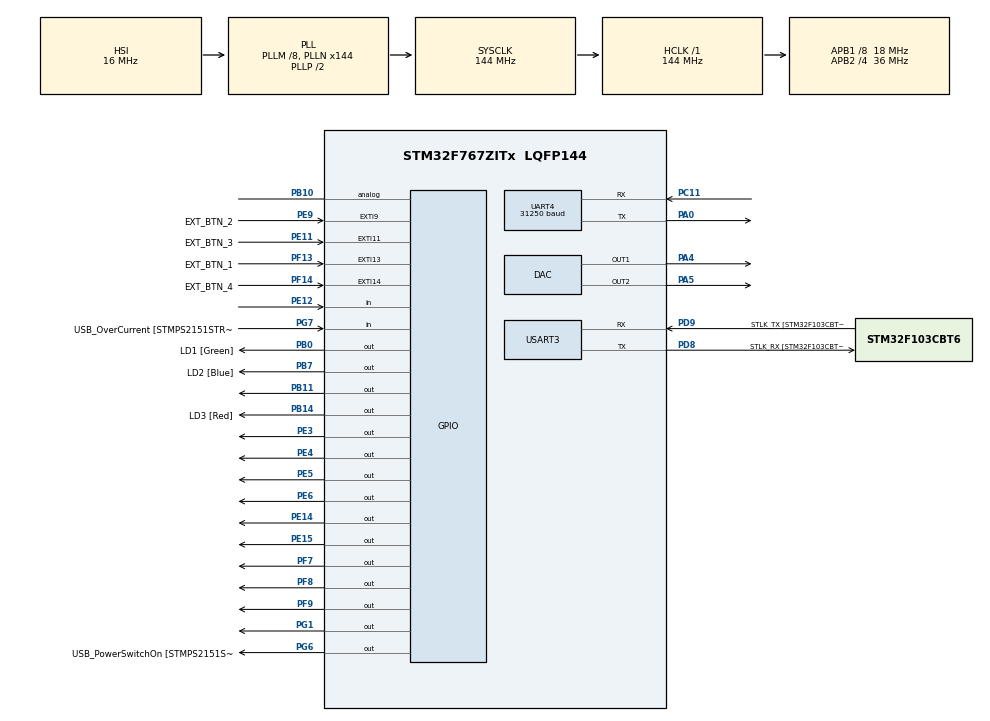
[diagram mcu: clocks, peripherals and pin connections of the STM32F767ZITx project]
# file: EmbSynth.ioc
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CORTEX_M7.CPU_ICache=Disabled
CORTEX_M7.FlashInterface=AXI_Enabled
DAC.DAC_OutputBuffer=DAC_OUTPUTBUFFER_ENABLE
DAC.DAC_Trigger=DAC_TRIGGER_T6_TRGO
DAC.DAC_Trigger2=DAC_TRIGGER_T6_TRGO
Dma.DAC1.1.Direction=DMA_MEMORY_TO_PERIPH
Dma.DAC1.1.FIFOMode=DMA_FIFOMODE_DISABLE
Dma.DAC1.1.Instance=DMA1_Stream5
Dma.DAC1.1.MemDataAlignment=DMA_MDATAALIGN_WORD
Dma.DAC1.1.MemInc=DMA_MINC_ENABLE
Dma.DAC1.1.Mode=DMA_CIRCULAR
Dma.DAC1.1.PeriphDataAlignment=DMA_PDATAALIGN_WORD
Dma.DAC1.1.PeriphInc=DMA_PINC_DISABLE
Dma.DAC1.1.Priority=DMA_PRIORITY_HIGH
Dma.DAC2.2.Direction=DMA_MEMORY_TO_PERIPH
Dma.DAC2.2.FIFOMode=DMA_FIFOMODE_DISABLE
Dma.DAC2.2.Instance=DMA1_Stream6
Dma.DAC2.2.MemDataAlignment=DMA_MDATAALIGN_WORD
Dma.DAC2.2.MemInc=DMA_MINC_ENABLE
Dma.DAC2.2.Mode=DMA_CIRCULAR
Dma.DAC2.2.PeriphDataAlignment=DMA_PDATAALIGN_WORD
Dma.DAC2.2.PeriphInc=DMA_PINC_DISABLE
Dma.DAC2.2.Priority=DMA_PRIORITY_HIGH
Dma.Request0=UART4_RX
Dma.Request1=DAC1
Dma.Request2=DAC2
Dma.UART4_RX.0.Direction=DMA_PERIPH_TO_MEMORY
Dma.UART4_RX.0.FIFOMode=DMA_FIFOMODE_DISABLE
Dma.UART4_RX.0.Instance=DMA1_Stream2
Dma.UART4_RX.0.MemDataAlignment=DMA_MDATAALIGN_BYTE
Dma.UART4_RX.0.MemInc=DMA_MINC_ENABLE
Dma.UART4_RX.0.Mode=DMA_CIRCULAR
Dma.UART4_RX.0.PeriphDataAlignment=DMA_PDATAALIGN_BYTE
Dma.UART4_RX.0.PeriphInc=DMA_PINC_DISABLE
Dma.UART4_RX.0.Priority=DMA_PRIORITY_HIGH
Mcu.Family=STM32F7
Mcu.Name=STM32F767ZITx
Mcu.Package=LQFP144
NVIC.DMA1_Stream2_IRQn=true\:0\:0\:false\:false\:true\:false\:true
NVIC.DMA1_Stream5_IRQn=true\:0\:0\:false\:false\:true\:false\:true
NVIC.DMA1_Stream6_IRQn=true\:0\:0\:false\:false\:true\:false\:true
NVIC.EXTI15_10_IRQn=true\:0\:0\:false\:false\:true\:true\:true
NVIC.EXTI9_5_IRQn=true\:0\:0\:false\:false\:true\:true\:true
NVIC.PriorityGroup=NVIC_PRIORITYGROUP_4
NVIC.TIM2_IRQn=true\:0\:0\:false\:false\:true\:true\:true
PA0/WKUP.Mode=Asynchronous
PA0/WKUP.Signal=UART4_TX
PA1.GPIO_Label=RMII_REF_CLK [LAN8742A-CZ-TR_REFCLK0]
PA1.Signal=ETH_REF_CLK
PA10.GPIO_Label=USB_ID
PA10.Signal=USB_OTG_FS_ID
PA11.GPIO_Label=USB_DM
PA11.Signal=USB_OTG_FS_DM
PA12.GPIO_Label=USB_DP
PA12.Signal=USB_OTG_FS_DP
PA13.GPIO_Label=TMS
PA13.Mode=Serial_Wire
PA13.Signal=SYS_JTMS-SWDIO
PA14.GPIO_Label=TCK
PA14.Mode=Serial_Wire
PA14.Signal=SYS_JTCK-SWCLK
PA2.GPIO_Label=RMII_MDIO [LAN8742A-CZ-TR_MDIO]
PA2.Signal=ETH_MDIO
PA4.Signal=COMP_DAC1_group
PA5.Signal=COMP_DAC2_group
PA7.GPIO_Label=RMII_CRS_DV [LAN8742A-CZ-TR_CRS_DV]
PA7.Signal=ETH_CRS_DV
PA8.GPIO_Label=USB_SOF [TP1]
PA8.Signal=USB_OTG_FS_SOF
PA9.GPIO_Label=USB_VBUS
PA9.Signal=USB_OTG_FS_VBUS
PB0.GPIO_Label=LD1 [Green]
PB0.Signal=GPIO_Output
PB10.Signal=GPIO_Analog
PB11.Signal=GPIO_Output
PB13.GPIO_Label=RMII_TXD1 [LAN8742A-CZ-TR_TXD1]
PB13.Signal=ETH_TXD1
PB14.GPIO_Label=LD3 [Red]
PB14.Signal=GPIO_Output
PB3.GPIO_Label=SWO
PB3.Signal=SYS_JTDO-SWO
PB7.GPIO_Label=LD2 [Blue]
PB7.Signal=GPIO_Output
PC1.GPIO_Label=RMII_MDC [LAN8742A-CZ-TR_MDC]
PC1.Signal=ETH_MDC
PC11.Mode=Asynchronous
PC11.Signal=UART4_RX
PC14/OSC32_IN.Mode=LSE-External-Oscillator
PC14/OSC32_IN.Signal=RCC_OSC32_IN
PC15/OSC32_OUT.Mode=LSE-External-Oscillator
PC15/OSC32_OUT.Signal=RCC_OSC32_OUT
PC4.GPIO_Label=RMII_RXD0 [LAN8742A-CZ-TR_RXD0]
PC4.Signal=ETH_RXD0
PC5.GPIO_Label=RMII_RXD1 [LAN8742A-CZ-TR_RXD1]
PC5.Signal=ETH_RXD1
PD8.GPIO_Label=STLK_RX [STM32F103CBT6_PA3]
PD8.Mode=Asynchronous
PD8.Signal=USART3_TX
PD9.GPIO_Label=STLK_TX [STM32F103CBT6_PA2]
PD9.Mode=Asynchronous
PD9.Signal=USART3_RX
PE11.GPIO_Label=EXT_BTN_3
PE11.GPIO_ModeDefaultEXTI=GPIO_MODE_IT_FALLING
PE11.GPIO_PuPd=GPIO_PULLUP
PE11.Signal=GPXTI11
PE12.Signal=GPIO_Input
PE14.Signal=GPIO_Output
PE15.Signal=GPIO_Output
PE3.Signal=GPIO_Output
PE4.Signal=GPIO_Output
PE5.Signal=GPIO_Output
PE6.Signal=GPIO_Output
PE9.GPIO_Label=EXT_BTN_2
PE9.GPIO_ModeDefaultEXTI=GPIO_MODE_IT_FALLING
PE9.GPIO_PuPd=GPIO_PULLUP
PE9.Signal=GPXTI9
PF13.GPIO_Label=EXT_BTN_1
PF13.GPIO_ModeDefaultEXTI=GPIO_MODE_IT_FALLING
PF13.GPIO_PuPd=GPIO_PULLUP
PF13.Signal=GPXTI13
PF14.GPIO_Label=EXT_BTN_4
PF14.GPIO_ModeDefaultEXTI=GPIO_MODE_IT_FALLING
PF14.GPIO_PuPd=GPIO_PULLUP
PF14.Signal=GPXTI14
PF7.Signal=GPIO_Output
PF8.Signal=GPIO_Output
PF9.Signal=GPIO_Output
PG1.Signal=GPIO_Output
PG11.GPIO_Label=RMII_TX_EN [LAN8742A-CZ-TR_TXEN]
PG11.Signal=ETH_TX_EN
PG13.GPIO_Label=RMII_TXD0 [LAN8742A-CZ-TR_TXD0]
PG13.Signal=ETH_TXD0
PG6.GPIO_Label=USB_PowerSwitchOn [STMPS2151STR_EN]
PG6.Signal=GPIO_Output
PG7.GPIO_Label=USB_OverCurrent [STMPS2151STR_FAULT]
PG7.Signal=GPIO_Input
PH0/OSC_IN.GPIO_Label=MCO [STM32F103CBT6_PA8]
PH0/OSC_IN.Signal=RCC_OSC_IN
PH1/OSC_OUT.Signal=RCC_OSC_OUT
ProjectManager.HeapSize=0x200
ProjectManager.StackSize=0x400
ProjectManager.TargetToolchain=STM32CubeIDE
RCC.48MHZClocksFreq_Value=24000000
RCC.AHBFreq_Value=144000000
RCC.APB1CLKDivider=RCC_HCLK_DIV8
RCC.APB1Freq_Value=18000000
RCC.APB1TimFreq_Value=36000000
RCC.APB2CLKDivider=RCC_HCLK_DIV4
RCC.APB2Freq_Value=36000000
RCC.APB2TimFreq_Value=72000000
RCC.CortexFreq_Value=144000000
RCC.HCLKFreq_Value=144000000
RCC.HSE_VALUE=8000000
RCC.HSI_VALUE=16000000
RCC.PLLM=8
RCC.PLLMUL=RCC_PLL_MUL9
RCC.PLLN=144
RCC.PLLQ=4
RCC.PRESCALERUSB=RCC_USBCLKSOURCE_PLL_DIV1_5
RCC.SYSCLKFreq_VALUE=144000000
RCC.SYSCLKSource=RCC_SYSCLKSOURCE_PLLCLK
RCC.SYSCLKSourceVirtual=RCC_SYSCLKSOURCE_PLLCLK
RCC.USBFreq_Value=72000000
RCC.VCOOutputFreq_Value=288000000
SH.COMP_DAC1_group.0=DAC_OUT1,DAC_OUT1
SH.COMP_DAC2_group.0=DAC_OUT2,DAC_OUT2
TIM1.Period=0xffff-1
TIM1.Prescaler=72-1
TIM2.Period=40-1
TIM2.Prescaler=36000-1
TIM6.Period=15-1
TIM6.Prescaler=55-1
TIM6.TIM_MasterOutputTrigger=TIM_TRGO_UPDATE
UART4.BaudRate=31250
USART3.VirtualMode-Asynchronous=VM_ASYNC
VP_TIM1_VS_ClockSourceINT.Mode=Internal
VP_TIM2_VS_ClockSourceINT.Mode=Internal
VP_TIM6_VS_ClockSourceINT.Mode=Enable_Timer
board=NUCLEO-F767ZI

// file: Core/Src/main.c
/* USER CODE BEGIN Header */
/**
 ******************************************************************************
 * @file           : main.c
 * @brief          : Main program body
 ******************************************************************************
 * @attention
 *
 * <h2><center>&copy; Copyright (c) 2020 STMicroelectronics.
 * All rights reserved.</center></h2>
 *
 * This software component is licensed by ST under BSD 3-Clause license,
 * the "License"; You may not use this file except in compliance with the
 * License. You may obtain a copy of the License at:
 *                        opensource.org/licenses/BSD-3-Clause
 *
 ******************************************************************************
 */
/* USER CODE END Header */
#include "main.h"

/* USER CODE BEGIN Includes */
#include <stdbool.h>
#include "math.h"
#include "fonts.h"
#include "tft.h"
#include "functions.h"
/* USER CODE END Includes */

/* USER CODE BEGIN PD */
#define RX_BUFFER_SIZE 1
#define NOTE_BUFFER_SIZE 1
#define PLAYED_NOTES_BUFFER_SIZE 5
#define C2 36
#define B5 83
#define NS 500
#define PI 3.1415926
/* USER CODE END PD */

DAC_HandleTypeDef hdac;
DMA_HandleTypeDef hdma_dac1;
DMA_HandleTypeDef hdma_dac2;

TIM_HandleTypeDef htim1;
TIM_HandleTypeDef htim2;
TIM_HandleTypeDef htim6;

UART_HandleTypeDef huart4;
UART_HandleTypeDef huart3;
DMA_HandleTypeDef hdma_uart4_rx;

/* USER CODE BEGIN PV */

// LCD
uint16_t ID = 0;
uint8_t current_am_selection = 0;
uint8_t current_fm_selection = 0;
uint8_t current_envelope_selection = 0;
uint8_t current_signal_selection = 0;

// Serial
uint8_t rx_buffer[RX_BUFFER_SIZE] = {0};
uint8_t note_buffer[NOTE_BUFFER_SIZE] = {0};
uint8_t note_cnt = 0;
uint8_t received_note_buffer = 0;
bool repeated_note_flag = false;

// Interrupción
volatile bool EXT_BTN_1_state = true;
volatile bool EXT_BTN_2_state = true;
volatile bool EXT_BTN_3_state = true;
volatile bool EXT_BTN_4_state = true;

// Audio
uint8_t played_notes_buffer[PLAYED_NOTES_BUFFER_SIZE] = {0};

uint16_t sine_LUT [] = {
		2048, 2073, 2099, 2125, 2151, 2176, 2202, 2228, 2253, 2279, 2305, 2330, 2356, 2381, 2407,
		2432, 2457, 2482, 2508, 2533, 2558, 2583, 2607, 2632, 2657, 2681, 2706, 2730, 2755, 2779,
		2803, 2827, 2850, 2874, 2898, 2921, 2944, 2967, 2990, 3013, 3036, 3058, 3081, 3103, 3125,
		3147, 3168, 3190, 3211, 3232, 3253, 3274, 3294, 3315, 3335, 3355, 3375, 3394, 3413, 3432,
		3451, 3470, 3488, 3507, 3525, 3542, 3560, 3577, 3594, 3611, 3627, 3644, 3660, 3675, 3691,
		3706, 3721, 3736, 3750, 3765, 3778, 3792, 3805, 3819, 3831, 3844, 3856, 3868, 3880, 3891,
		3902, 3913, 3923, 3934, 3943, 3953, 3962, 3971, 3980, 3988, 3996, 4004, 4012, 4019, 4026,
		4032, 4038, 4044, 4050, 4055, 4060, 4064, 4069, 4073, 4076, 4080, 4083, 4085, 4088, 4090,
		4091, 4093, 4094, 4095, 4095, 4095, 4095, 4094, 4093, 4092, 4091, 4089, 4086, 4084, 4081,
		4078, 4074, 4071, 4067, 4062, 4057, 4052, 4047, 4041, 4035, 4029, 4022, 4015, 4008, 4000,
		3992, 3984, 3976, 3967, 3958, 3948, 3939, 3928, 3918, 3908, 3897, 3885, 3874, 3862, 3850,
		3838, 3825, 3812, 3799, 3785, 3772, 3758, 3743, 3729, 3714, 3699, 3683, 3668, 3652, 3636,
		3619, 3603, 3586, 3569, 3551, 3534, 3516, 3498, 3479, 3461, 3442, 3423, 3404, 3384, 3365,
		3345, 3325, 3305, 3284, 3263, 3243, 3222, 3200, 3179, 3157, 3136, 3114, 3092, 3069, 3047,
		3024, 3002, 2979, 2956, 2933, 2909, 2886, 2862, 2838, 2815, 2791, 2767, 2742, 2718, 2694,
		2669, 2645, 2620, 2595, 2570, 2545, 2520, 2495, 2470, 2445, 2419, 2394, 2368, 2343, 2317,
		2292, 2266, 2241, 2215, 2189, 2163, 2138, 2112, 2086, 2060, 2035, 2009, 1983, 1957, 1932,
		1906, 1880, 1854, 1829, 1803, 1778, 1752, 1727, 1701, 1676, 1650, 1625, 1600, 1575, 1550,
		1525, 1500, 1475, 1450, 1426, 1401, 1377, 1353, 1328, 1304, 1280, 1257, 1233, 1209, 1186,
		1162, 1139, 1116, 1093, 1071, 1048, 1026, 1003, 981, 959, 938, 916, 895, 873, 852,
		832, 811, 790, 770, 750, 730, 711, 691, 672, 653, 634, 616, 597, 579, 561,
		544, 526, 509, 492, 476, 459, 443, 427, 412, 396, 381, 366, 352, 337, 323,
		310, 296, 283, 270, 257, 245, 233, 221, 210, 198, 187, 177, 167, 156, 147,
		137, 128, 119, 111, 103, 95, 87, 80, 73, 66, 60, 54, 48, 43, 38,
		33, 28, 24, 21, 17, 14, 11, 9, 6, 4, 3, 2, 1, 0, 0,
		0, 0, 1, 2, 4, 5, 7, 10, 12, 15, 19, 22, 26, 31, 35,
		40, 45, 51, 57, 63, 69, 76, 83, 91, 99, 107, 115, 124, 133, 142,
		152, 161, 172, 182, 193, 204, 215, 227, 239, 251, 264, 276, 290, 303, 317,
		330, 345, 359, 374, 389, 404, 420, 435, 451, 468, 484, 501, 518, 535, 553,
		570, 588, 607, 625, 644, 663, 682, 701, 720, 740, 760, 780, 801, 821, 842,
		863, 884, 905, 927, 948, 970, 992, 1014, 1037, 1059, 1082, 1105, 1128, 1151, 1174,
		1197, 1221, 1245, 1268, 1292, 1316, 1340, 1365, 1389, 1414, 1438, 1463, 1488, 1512, 1537,
		1562, 1587, 1613, 1638, 1663, 1688, 1714, 1739, 1765, 1790, 1816, 1842, 1867, 1893, 1919,
		1944, 1970, 1996, 2022, 2047
};

uint16_t sawtooth_LUT [] = {
		0, 8, 16, 25, 33, 41, 49, 57, 66, 74, 82, 90, 98, 107, 115,
		123, 131, 140, 148, 156, 164, 172, 181, 189, 197, 205, 213, 222, 230, 238,
		246, 254, 263, 271, 279, 287, 295, 304, 312, 320, 328, 336, 345, 353, 361,
		369, 377, 386, 394, 402, 410, 419, 427, 435, 443, 451, 460, 468, 476, 484,
		492, 501, 509, 517, 525, 533, 542, 550, 558, 566, 574, 583, 591, 599, 607,
		615, 624, 632, 640, 648, 657, 665, 673, 681, 689, 698, 706, 714, 722, 730,
		739, 747, 755, 763, 771, 780, 788, 796, 804, 812, 821, 829, 837, 845, 853,
		862, 870, 878, 886, 894, 903, 911, 919, 927, 936, 944, 952, 960, 968, 977,
		985, 993, 1001, 1009, 1018, 1026, 1034, 1042, 1050, 1059, 1067, 1075, 1083, 1091, 1100,
		1108, 1116, 1124, 1132, 1141, 1149, 1157, 1165, 1174, 1182, 1190, 1198, 1206, 1215, 1223,
		1231, 1239, 1247, 1256, 1264, 1272, 1280, 1288, 1297, 1305, 1313, 1321, 1329, 1338, 1346,
		1354, 1362, 1370, 1379, 1387, 1395, 1403, 1412, 1420, 1428, 1436, 1444, 1453, 1461, 1469,
		1477, 1485, 1494, 1502, 1510, 1518, 1526, 1535, 1543, 1551, 1559, 1567, 1576, 1584, 1592,
		1600, 1608, 1617, 1625, 1633, 1641, 1649, 1658, 1666, 1674, 1682, 1691, 1699, 1707, 1715,
		1723, 1732, 1740, 1748, 1756, 1764, 1773, 1781, 1789, 1797, 1805, 1814, 1822, 1830, 1838,
		1846, 1855, 1863, 1871, 1879, 1887, 1896, 1904, 1912, 1920, 1929, 1937, 1945, 1953, 1961,
		1970, 1978, 1986, 1994, 2002, 2011, 2019, 2027, 2035, 2043, 2052, 2060, 2068, 2076, 2084,
		2093, 2101, 2109, 2117, 2125, 2134, 2142, 2150, 2158, 2166, 2175, 2183, 2191, 2199, 2208,
		2216, 2224, 2232, 2240, 2249, 2257, 2265, 2273, 2281, 2290, 2298, 2306, 2314, 2322, 2331,
		2339, 2347, 2355, 2363, 2372, 2380, 2388, 2396, 2404, 2413, 2421, 2429, 2437, 2446, 2454,
		2462, 2470, 2478, 2487, 2495, 2503, 2511, 2519, 2528, 2536, 2544, 2552, 2560, 2569, 2577,
		2585, 2593, 2601, 2610, 2618, 2626, 2634, 2642, 2651, 2659, 2667, 2675, 2683, 2692, 2700,
		2708, 2716, 2725, 2733, 2741, 2749, 2757, 2766, 2774, 2782, 2790, 2798, 2807, 2815, 2823,
		2831, 2839, 2848, 2856, 2864, 2872, 2880, 2889, 2897, 2905, 2913, 2921, 2930, 2938, 2946,
		2954, 2963, 2971, 2979, 2987, 2995, 3004, 3012, 3020, 3028, 3036, 3045, 3053, 3061, 3069,
		3077, 3086, 3094, 3102, 3110, 3118, 3127, 3135, 3143, 3151, 3159, 3168, 3176, 3184, 3192,
		3201, 3209, 3217, 3225, 3233, 3242, 3250, 3258, 3266, 3274, 3283, 3291, 3299, 3307, 3315,
		3324, 3332, 3340, 3348, 3356, 3365, 3373, 3381, 3389, 3397, 3406, 3414, 3422, 3430, 3438,
		3447, 3455, 3463, 3471, 3480, 3488, 3496, 3504, 3512, 3521, 3529, 3537, 3545, 3553, 3562,
		3570, 3578, 3586, 3594, 3603, 3611, 3619, 3627, 3635, 3644, 3652, 3660, 3668, 3676, 3685,
		3693, 3701, 3709, 3718, 3726, 3734, 3742, 3750, 3759, 3767, 3775, 3783, 3791, 3800, 3808,
		3816, 3824, 3832, 3841, 3849, 3857, 3865, 3873, 3882, 3890, 3898, 3906, 3914, 3923, 3931,
		3939, 3947, 3955, 3964, 3972, 3980, 3988, 3997, 4005, 4013, 4021, 4029, 4038, 4046, 4054,
		4062, 4070, 4079, 4087, 0
};

uint16_t triangle_LUT [] = {
		0, 16, 33, 49, 66, 82, 98, 115, 131, 148, 164, 181, 197, 213, 230,
		246, 263, 279, 295, 312, 328, 345, 361, 377, 394, 410, 427, 443, 460, 476,
		492, 509, 525, 542, 558, 574, 591, 607, 624, 640, 657, 673, 689, 706, 722,
		739, 755, 771, 788, 804, 821, 837, 853, 870, 886, 903, 919, 936, 952, 968,
		985, 1001, 1018, 1034, 1050, 1067, 1083, 1100, 1116, 1132, 1149, 1165, 1182, 1198, 1215,
		1231, 1247, 1264, 1280, 1297, 1313, 1329, 1346, 1362, 1379, 1395, 1412, 1428, 1444, 1461,
		1477, 1494, 1510, 1526, 1543, 1559, 1576, 1592, 1608, 1625, 1641, 1658, 1674, 1691, 1707,
		1723, 1740, 1756, 1773, 1789, 1805, 1822, 1838, 1855, 1871, 1887, 1904, 1920, 1937, 1953,
		1970, 1986, 2002, 2019, 2035, 2052, 2068, 2084, 2101, 2117, 2134, 2150, 2166, 2183, 2199,
		2216, 2232, 2249, 2265, 2281, 2298, 2314, 2331, 2347, 2363, 2380, 2396, 2413, 2429, 2446,
		2462, 2478, 2495, 2511, 2528, 2544, 2560, 2577, 2593, 2610, 2626, 2642, 2659, 2675, 2692,
		2708, 2725, 2741, 2757, 2774, 2790, 2807, 2823, 2839, 2856, 2872, 2889, 2905, 2921, 2938,
		2954, 2971, 2987, 3004, 3020, 3036, 3053, 3069, 3086, 3102, 3118, 3135, 3151, 3168, 3184,
		3201, 3217, 3233, 3250, 3266, 3283, 3299, 3315, 3332, 3348, 3365, 3381, 3397, 3414, 3430,
		3447, 3463, 3480, 3496, 3512, 3529, 3545, 3562, 3578, 3594, 3611, 3627, 3644, 3660, 3676,
		3693, 3709, 3726, 3742, 3759, 3775, 3791, 3808, 3824, 3841, 3857, 3873, 3890, 3906, 3923,
		3939, 3955, 3972, 3988, 4005, 4021, 4038, 4054, 4070, 4087, 4087, 4070, 4054, 4038, 4021,
		4005, 3988, 3972, 3955, 3939, 3923, 3906, 3890, 3873, 3857, 3841, 3824, 3808, 3791, 3775,
		3759, 3742, 3726, 3709, 3693, 3676, 3660, 3644, 3627, 3611, 3594, 3578, 3562, 3545, 3529,
		3512, 3496, 3480, 3463, 3447, 3430, 3414, 3397, 3381, 3365, 3348, 3332, 3315, 3299, 3283,
		3266, 3250, 3233, 3217, 3201, 3184, 3168, 3151, 3135, 3118, 3102, 3086, 3069, 3053, 3036,
		3020, 3004, 2987, 2971, 2954, 2938, 2921, 2905, 2889, 2872, 2856, 2839, 2823, 2807, 2790,
		2774, 2757, 2741, 2725, 2708, 2692, 2675, 2659, 2642, 2626, 2610, 2593, 2577, 2560, 2544,
		2528, 2511, 2495, 2478, 2462, 2446, 2429, 2413, 2396, 2380, 2363, 2347, 2331, 2314, 2298,
		2281, 2265, 2249, 2232, 2216, 2199, 2183, 2166, 2150, 2134, 2117, 2101, 2084, 2068, 2052,
		2035, 2019, 2002, 1986, 1970, 1953, 1937, 1920, 1904, 1887, 1871, 1855, 1838, 1822, 1805,
		1789, 1773, 1756, 1740, 1723, 1707, 1691, 1674, 1658, 1641, 1625, 1608, 1592, 1576, 1559,
		1543, 1526, 1510, 1494, 1477, 1461, 1444, 1428, 1412, 1395, 1379, 1362, 1346, 1329, 1313,
		1297, 1280, 1264, 1247, 1231, 1215, 1198, 1182, 1165, 1149, 1132, 1116, 1100, 1083, 1067,
		1050, 1034, 1018, 1001, 985, 968, 952, 936, 919, 903, 886, 870, 853, 837, 821,
		804, 788, 771, 755, 739, 722, 706, 689, 673, 657, 640, 624, 607, 591, 574,
		558, 542, 525, 509, 492, 476, 460, 443, 427, 410, 394, 377, 361, 345, 328,
		312, 295, 279, 263, 246, 230, 213, 197, 181, 164, 148, 131, 115, 98, 82,
		66, 49, 33, 16, 0
};

uint16_t square_LUT [] = {
		4095, 4095, 4095, 4095, 4095, 4095, 4095, 4095, 4095, 4095, 4095, 4095, 4095, 4095, 4095,
		4095, 4095, 4095, 4095, 4095, 4095, 4095, 4095, 4095, 4095, 4095, 4095, 4095, 4095, 4095,
		4095, 4095, 4095, 4095, 4095, 4095, 4095, 4095, 4095, 4095, 4095, 4095, 4095, 4095, 4095,
		4095, 4095, 4095, 4095, 4095, 4095, 4095, 4095, 4095, 4095, 4095, 4095, 4095, 4095, 4095,
		4095, 4095, 4095, 4095, 4095, 4095, 4095, 4095, 4095, 4095, 4095, 4095, 4095, 4095, 4095,
		4095, 4095, 4095, 4095, 4095, 4095, 4095, 4095, 4095, 4095, 4095, 4095, 4095, 4095, 4095,
		4095, 4095, 4095, 4095, 4095, 4095, 4095, 4095, 4095, 4095, 4095, 4095, 4095, 4095, 4095,
		4095, 4095, 4095, 4095, 4095, 4095, 4095, 4095, 4095, 4095, 4095, 4095, 4095, 4095, 4095,
		4095, 4095, 4095, 4095, 4095, 4095, 4095, 4095, 4095, 4095, 4095, 4095, 4095, 4095, 4095,
		4095, 4095, 4095, 4095, 4095, 4095, 4095, 4095, 4095, 4095, 4095, 4095, 4095, 4095, 4095,
		4095, 4095, 4095, 4095, 4095, 4095, 4095, 4095, 4095, 4095, 4095, 4095, 4095, 4095, 4095,
		4095, 4095, 4095, 4095, 4095, 4095, 4095, 4095, 4095, 4095, 4095, 4095, 4095, 4095, 4095,
		4095, 4095, 4095, 4095, 4095, 4095, 4095, 4095, 4095, 4095, 4095, 4095, 4095, 4095, 4095,
		4095, 4095, 4095, 4095, 4095, 4095, 4095, 4095, 4095, 4095, 4095, 4095, 4095, 4095, 4095,
		4095, 4095, 4095, 4095, 4095, 4095, 4095, 4095, 4095, 4095, 4095, 4095, 4095, 4095, 4095,
		4095, 4095, 4095, 4095, 4095, 4095, 4095, 4095, 4095, 4095, 4095, 4095, 4095, 4095, 4095,
		4095, 4095, 4095, 4095, 4095, 4095, 4095, 4095, 4095, 4095, 0, 0, 0, 0, 0,
		0, 0, 0, 0, 0, 0, 0, 0, 0, 0, 0, 0, 0, 0, 0,
		0, 0, 0, 0, 0, 0, 0, 0, 0, 0, 0, 0, 0, 0, 0,
		0, 0, 0, 0, 0, 0, 0, 0, 0, 0, 0, 0, 0, 0, 0,
		0, 0, 0, 0, 0, 0, 0, 0, 0, 0, 0, 0, 0, 0, 0,
		0, 0, 0, 0, 0, 0, 0, 0, 0, 0, 0, 0, 0, 0, 0,
		0, 0, 0, 0, 0, 0, 0, 0, 0, 0, 0, 0, 0, 0, 0,
		0, 0, 0, 0, 0, 0, 0, 0, 0, 0, 0, 0, 0, 0, 0,
		0, 0, 0, 0, 0, 0, 0, 0, 0, 0, 0, 0, 0, 0, 0,
		0, 0, 0, 0, 0, 0, 0, 0, 0, 0, 0, 0, 0, 0, 0,
		0, 0, 0, 0, 0, 0, 0, 0, 0, 0, 0, 0, 0, 0, 0,
		0, 0, 0, 0, 0, 0, 0, 0, 0, 0, 0, 0, 0, 0, 0,
		0, 0, 0, 0, 0, 0, 0, 0, 0, 0, 0, 0, 0, 0, 0,
		0, 0, 0, 0, 0, 0, 0, 0, 0, 0, 0, 0, 0, 0, 0,
		0, 0, 0, 0, 0, 0, 0, 0, 0, 0, 0, 0, 0, 0, 0,
		0, 0, 0, 0, 0, 0, 0, 0, 0, 0, 0, 0, 0, 0, 0,
		0, 0, 0, 0, 0, 0, 0, 0, 0, 0, 0, 0, 0, 0, 0,
		0, 0, 0, 0, 4095
};

uint16_t PSC_LUT [] = {3, 2, 1, 1, 1, 1, 1, 1, 1, 1, 1, 1, 1, 1, 1, 1, 1, 1, 1, 1, 1, 1, 1, 1, 1, 1, 1, 1, 1, 1, 1, 1, 1, 1, 1, 1, 1, 1, 1, 1, 1, 1, 1, 1, 1, 1, 1, 1, 1, 1, 1, 1, 1, 1, 1, 1, 1, 1, 1, 1};
uint16_t ARR_LUT [] = {367, 519, 981, 926, 874, 825, 778, 735, 693, 655, 618, 583, 550, 519, 490, 463, 437, 412, 389, 367, 347, 327, 309, 292, 275, 260, 245, 231, 218, 206, 195, 184, 173, 164, 154, 146, 138, 130, 123, 116, 109, 103, 97, 92, 87, 82, 77, 73, 69, 65, 61, 58, 55, 52, 49, 46, 43, 41, 39, 36};

uint16_t square_to_sine_modulation [] = {
		2048, 2803, 3451, 3902, 4091, 3992, 3619, 3024, 2292, 1525, 832, 310, 33, 40, 330,
		863, 1562, 2330, 3058, 3644, 4004, 4089, 3885, 3423, 2767, 2009, 1257, 616, 177, 2,
		115, 501, 1105, 1842, 2607, 3294, 3805, 4069, 4047, 3743, 3200, 2495, 1727, 1003, 427,
		80, 10, 227, 701, 1365, 2125, 2874, 3507, 3934, 4095, 3967, 3569, 2956, 2215, 1450,
		770, 270, 21, 57, 374, 927, 1638, 2407, 3125, 3691, 4026, 4081, 3850, 3365, 2694,
		1932, 1186, 561, 147, 0, 142, 553, 1174, 1919, 2681, 3355, 3844, 4080, 4029, 3699,
		3136, 2419, 1650, 938, 381, 60, 19, 264, 760, 1438, 2202, 2944, 3560, 3962, 4095,
		3939, 3516, 2886, 2138, 1377, 711, 233, 11, 76, 420, 992, 1714, 2482, 3190, 3736,
		4044, 4071, 3812, 3305, 2620, 1854, 1116, 509, 119, 1, 172, 607, 1245, 1996, 2755,
		3413, 3880, 4088, 4008, 3652, 3069, 2343, 1575, 873, 337, 43, 31, 303, 821, 1512,
		2279, 3013, 3611, 3988, 4092, 3908, 3461, 2815, 2060, 1304, 653, 198, 4, 99, 468,
		1059, 1790, 2558, 3253, 3778, 4060, 4057, 3772, 3243, 2545, 1778, 1048, 459, 95, 5,
		204, 663, 1316, 2073, 2827, 3470, 3913, 4093, 3984, 3603, 3002, 2266, 1500, 811, 296,
		28, 45, 345, 884, 1587, 2356, 3081, 3660, 4012, 4086, 3874, 3404, 2742, 1983, 1233,
		597, 167, 1, 124, 518, 1128, 1867, 2632, 3315, 3819, 4073, 4041, 3729, 3179, 2470,
		1701, 981, 412, 73, 12, 239, 720, 1389, 2151, 2898, 3525, 3943, 4095, 3958, 3551,
		2933, 2189, 1426, 750, 257, 17, 63, 389, 948, 1663, 0, 0, 0, 0, 0,
		0, 0, 0, 0, 0, 0, 0, 0, 0, 0, 0, 0, 0, 0, 0,
		0, 0, 0, 0, 0, 0, 0, 0, 0, 0, 0, 0, 0, 0, 0,
		0, 0, 0, 0, 0, 0, 0, 0, 0, 0, 0, 0, 0, 0, 0,
		0, 0, 0, 0, 0, 0, 0, 0, 0, 0, 0, 0, 0, 0, 0,
		0, 0, 0, 0, 0, 0, 0, 0, 0, 0, 0, 0, 0, 0, 0,
		0, 0, 0, 0, 0, 0, 0, 0, 0, 0, 0, 0, 0, 0, 0,
		0, 0, 0, 0, 0, 0, 0, 0, 0, 0, 0, 0, 0, 0, 0,
		0, 0, 0, 0, 0, 0, 0, 0, 0, 0, 0, 0, 0, 0, 0,
		0, 0, 0, 0, 0, 0, 0, 0, 0, 0, 0, 0, 0, 0, 0,
		0, 0, 0, 0, 0, 0, 0, 0, 0, 0, 0, 0, 0, 0, 0,
		0, 0, 0, 0, 0, 0, 0, 0, 0, 0, 0, 0, 0, 0, 0,
		0, 0, 0, 0, 0, 0, 0, 0, 0, 0, 0, 0, 0, 0, 0,
		0, 0, 0, 0, 0, 0, 0, 0, 0, 0, 0, 0, 0, 0, 0,
		0, 0, 0, 0, 0, 0, 0, 0, 0, 0, 0, 0, 0, 0, 0,
		0, 0, 0, 0, 0, 0, 0, 0, 0, 0, 0, 0, 0, 0, 0,
		0, 0, 0, 0, 0, 0, 0, 0, 0, 0, 0, 0, 0, 0, 0,
		0, 0, 0, 0, 2047
};
uint16_t square_to_square_modulation [] = {
		4095, 4095, 4095, 4095, 4095, 4095, 4095, 4095, 4095, 0, 0, 0, 0, 0, 0,
		0, 0, 4095, 4095, 4095, 4095, 4095, 4095, 4095, 4095, 0, 0, 0, 0, 0,
		0, 0, 0, 0, 4095, 4095, 4095, 4095, 4095, 4095, 4095, 4095, 0, 0, 0,
		0, 0, 0, 0, 0, 4095, 4095, 4095, 4095, 4095, 4095, 4095, 4095, 4095, 0,
		0, 0, 0, 0, 0, 0, 0, 4095, 4095, 4095, 4095, 4095, 4095, 4095, 4095,
		0, 0, 0, 0, 0, 0, 0, 0, 0, 4095, 4095, 4095, 4095, 4095, 4095,
		4095, 4095, 0, 0, 0, 0, 0, 0, 0, 0, 4095, 4095, 4095, 4095, 4095,
		4095, 4095, 4095, 4095, 0, 0, 0, 0, 0, 0, 0, 0, 4095, 4095, 4095,
		4095, 4095, 4095, 4095, 4095, 0, 0, 0, 0, 0, 0, 0, 0, 0, 4095,
		4095, 4095, 4095, 4095, 4095, 4095, 4095, 0, 0, 0, 0, 0, 0, 0, 0,
		4095, 4095, 4095, 4095, 4095, 4095, 4095, 4095, 4095, 0, 0, 0, 0, 0, 0,
		0, 0, 4095, 4095, 4095, 4095, 4095, 4095, 4095, 4095, 0, 0, 0, 0, 0,
		0, 0, 0, 4095, 4095, 4095, 4095, 4095, 4095, 4095, 4095, 4095, 0, 0, 0,
		0, 0, 0, 0, 0, 4095, 4095, 4095, 4095, 4095, 4095, 4095, 4095, 0, 0,
		0, 0, 0, 0, 0, 0, 0, 4095, 4095, 4095, 4095, 4095, 4095, 4095, 4095,
		0, 0, 0, 0, 0, 0, 0, 0, 4095, 4095, 4095, 4095, 4095, 4095, 4095,
		4095, 4095, 0, 0, 0, 0, 0, 0, 0, 0, 0, 0, 0, 0, 0,
		0, 0, 0, 0, 0, 0, 0, 0, 0, 0, 0, 0, 0, 0, 0,
		0, 0, 0, 0, 0, 0, 0, 0, 0, 0, 0, 0, 0, 0, 0,
		0, 0, 0, 0, 0, 0, 0, 0, 0, 0, 0, 0, 0, 0, 0,
		0, 0, 0, 0, 0, 0, 0, 0, 0, 0, 0, 0, 0, 0, 0,
		0, 0, 0, 0, 0, 0, 0, 0, 0, 0, 0, 0, 0, 0, 0,
		0, 0, 0, 0, 0, 0, 0, 0, 0, 0, 0, 0, 0, 0, 0,
		0, 0, 0, 0, 0, 0, 0, 0, 0, 0, 0, 0, 0, 0, 0,
		0, 0, 0, 0, 0, 0, 0, 0, 0, 0, 0, 0, 0, 0, 0,
		0, 0, 0, 0, 0, 0, 0, 0, 0, 0, 0, 0, 0, 0, 0,
		0, 0, 0, 0, 0, 0, 0, 0, 0, 0, 0, 0, 0, 0, 0,
		0, 0, 0, 0, 0, 0, 0, 0, 0, 0, 0, 0, 0, 0, 0,
		0, 0, 0, 0, 0, 0, 0, 0, 0, 0, 0, 0, 0, 0, 0,
		0, 0, 0, 0, 0, 0, 0, 0, 0, 0, 0, 0, 0, 0, 0,
		0, 0, 0, 0, 0, 0, 0, 0, 0, 0, 0, 0, 0, 0, 0,
		0, 0, 0, 0, 0, 0, 0, 0, 0, 0, 0, 0, 0, 0, 0,
		0, 0, 0, 0, 0, 0, 0, 0, 0, 0, 0, 0, 0, 0, 0,
		0, 0, 0, 0, 4095
};
uint16_t square_to_triangle_modulation [] = {
		0, 492, 985, 1477, 1970, 2462, 2954, 3447, 3939, 3759, 3266, 2774, 2281, 1789, 1297,
		804, 312, 181, 673, 1165, 1658, 2150, 2642, 3135, 3627, 4070, 3578, 3086, 2593, 2101,
		1608, 1116, 624, 131, 361, 853, 1346, 1838, 2331, 2823, 3315, 3808, 3890, 3397, 2905,
		2413, 1920, 1428, 936, 443, 49, 542, 1034, 1526, 2019, 2511, 3004, 3496, 3988, 3709,
		3217, 2725, 2232, 1740, 1247, 755, 263, 230, 722, 1215, 1707, 2199, 2692, 3184, 3676,
		4021, 3529, 3036, 2544, 2052, 1559, 1067, 574, 82, 410, 903, 1395, 1887, 2380, 2872,
		3365, 3857, 3841, 3348, 2856, 2363, 1871, 1379, 886, 394, 98, 591, 1083, 1576, 2068,
		2560, 3053, 3545, 4038, 3660, 3168, 2675, 2183, 1691, 1198, 706, 213, 279, 771, 1264,
		1756, 2249, 2741, 3233, 3726, 3972, 3480, 2987, 2495, 2002, 1510, 1018, 525, 33, 460,
		952, 1444, 1937, 2429, 2921, 3414, 3906, 3791, 3299, 2807, 2314, 1822, 1329, 837, 345,
		148, 640, 1132, 1625, 2117, 2610, 3102, 3594, 4087, 3611, 3118, 2626, 2134, 1641, 1149,
		657, 164, 328, 821, 1313, 1805, 2298, 2790, 3283, 3775, 3923, 3430, 2938, 2446, 1953,
		1461, 968, 476, 16, 509, 1001, 1494, 1986, 2478, 2971, 3463, 3955, 3742, 3250, 2757,
		2265, 1773, 1280, 788, 295, 197, 689, 1182, 1674, 2166, 2659, 3151, 3644, 4054, 3562,
		3069, 2577, 2084, 1592, 1100, 607, 115, 377, 870, 1362, 1855, 2347, 2839, 3332, 3824,
		3873, 3381, 2889, 2396, 1904, 1412, 919, 427, 66, 558, 1050, 1543, 2035, 2528, 3020,
		3512, 4005, 3693, 3201, 2708, 2216, 1723, 1231, 739, 246, 0, 0, 0, 0, 0,
		0, 0, 0, 0, 0, 0, 0, 0, 0, 0, 0, 0, 0, 0, 0,
		0, 0, 0, 0, 0, 0, 0, 0, 0, 0, 0, 0, 0, 0, 0,
		0, 0, 0, 0, 0, 0, 0, 0, 0, 0, 0, 0, 0, 0, 0,
		0, 0, 0, 0, 0, 0, 0, 0, 0, 0, 0, 0, 0, 0, 0,
		0, 0, 0, 0, 0, 0, 0, 0, 0, 0, 0, 0, 0, 0, 0,
		0, 0, 0, 0, 0, 0, 0, 0, 0, 0, 0, 0, 0, 0, 0,
		0, 0, 0, 0, 0, 0, 0, 0, 0, 0, 0, 0, 0, 0, 0,
		0, 0, 0, 0, 0, 0, 0, 0, 0, 0, 0, 0, 0, 0, 0,
		0, 0, 0, 0, 0, 0, 0, 0, 0, 0, 0, 0, 0, 0, 0,
		0, 0, 0, 0, 0, 0, 0, 0, 0, 0, 0, 0, 0, 0, 0,
		0, 0, 0, 0, 0, 0, 0, 0, 0, 0, 0, 0, 0, 0, 0,
		0, 0, 0, 0, 0, 0, 0, 0, 0, 0, 0, 0, 0, 0, 0,
		0, 0, 0, 0, 0, 0, 0, 0, 0, 0, 0, 0, 0, 0, 0,
		0, 0, 0, 0, 0, 0, 0, 0, 0, 0, 0, 0, 0, 0, 0,
		0, 0, 0, 0, 0, 0, 0, 0, 0, 0, 0, 0, 0, 0, 0,
		0, 0, 0, 0, 0, 0, 0, 0, 0, 0, 0, 0, 0, 0, 0,
		0, 0, 0, 0, 0
};
uint16_t square_to_sawtooth_modulation [] = {
		0, 246, 492, 739, 985, 1231, 1477, 1723, 1970, 2216, 2462, 2708, 2954, 3201, 3447,
		3693, 3939, 90, 336, 583, 829, 1075, 1321, 1567, 1814, 2060, 2306, 2552, 2798, 3045,
		3291, 3537, 3783, 4029, 181, 427, 673, 919, 1165, 1412, 1658, 1904, 2150, 2396, 2642,
		2889, 3135, 3381, 3627, 3873, 25, 271, 517, 763, 1009, 1256, 1502, 1748, 1994, 2240,
		2487, 2733, 2979, 3225, 3471, 3718, 3964, 115, 361, 607, 853, 1100, 1346, 1592, 1838,
		2084, 2331, 2577, 2823, 3069, 3315, 3562, 3808, 4054, 205, 451, 698, 944, 1190, 1436,
		1682, 1929, 2175, 2421, 2667, 2913, 3159, 3406, 3652, 3898, 49, 295, 542, 788, 1034,
		1280, 1526, 1773, 2019, 2265, 2511, 2757, 3004, 3250, 3496, 3742, 3988, 140, 386, 632,
		878, 1124, 1370, 1617, 1863, 2109, 2355, 2601, 2848, 3094, 3340, 3586, 3832, 4079, 230,
		476, 722, 968, 1215, 1461, 1707, 1953, 2199, 2446, 2692, 2938, 3184, 3430, 3676, 3923,
		74, 320, 566, 812, 1059, 1305, 1551, 1797, 2043, 2290, 2536, 2782, 3028, 3274, 3521,
		3767, 4013, 164, 410, 657, 903, 1149, 1395, 1641, 1887, 2134, 2380, 2626, 2872, 3118,
		3365, 3611, 3857, 8, 254, 501, 747, 993, 1239, 1485, 1732, 1978, 2224, 2470, 2716,
		2963, 3209, 3455, 3701, 3947, 98, 345, 591, 837, 1083, 1329, 1576, 1822, 2068, 2314,
		2560, 2807, 3053, 3299, 3545, 3791, 4038, 189, 435, 681, 927, 1174, 1420, 1666, 1912,
		2158, 2404, 2651, 2897, 3143, 3389, 3635, 3882, 33, 279, 525, 771, 1018, 1264, 1510,
		1756, 2002, 2249, 2495, 2741, 2987, 3233, 3480, 3726, 3972, 0, 0, 0, 0, 0,
		0, 0, 0, 0, 0, 0, 0, 0, 0, 0, 0, 0, 0, 0, 0,
		0, 0, 0, 0, 0, 0, 0, 0, 0, 0, 0, 0, 0, 0, 0,
		0, 0, 0, 0, 0, 0, 0, 0, 0, 0, 0, 0, 0, 0, 0,
		0, 0, 0, 0, 0, 0, 0, 0, 0, 0, 0, 0, 0, 0, 0,
		0, 0, 0, 0, 0, 0, 0, 0, 0, 0, 0, 0, 0, 0, 0,
		0, 0, 0, 0, 0, 0, 0, 0, 0, 0, 0, 0, 0, 0, 0,
		0, 0, 0, 0, 0, 0, 0, 0, 0, 0, 0, 0, 0, 0, 0,
		0, 0, 0, 0, 0, 0, 0, 0, 0, 0, 0, 0, 0, 0, 0,
		0, 0, 0, 0, 0, 0, 0, 0, 0, 0, 0, 0, 0, 0, 0,
		0, 0, 0, 0, 0, 0, 0, 0, 0, 0, 0, 0, 0, 0, 0,
		0, 0, 0, 0, 0, 0, 0, 0, 0, 0, 0, 0, 0, 0, 0,
		0, 0, 0, 0, 0, 0, 0, 0, 0, 0, 0, 0, 0, 0, 0,
		0, 0, 0, 0, 0, 0, 0, 0, 0, 0, 0, 0, 0, 0, 0,
		0, 0, 0, 0, 0, 0, 0, 0, 0, 0, 0, 0, 0, 0, 0,
		0, 0, 0, 0, 0, 0, 0, 0, 0, 0, 0, 0, 0, 0, 0,
		0, 0, 0, 0, 0, 0, 0, 0, 0, 0, 0, 0, 0, 0, 0,
		0, 0, 0, 0, 0
};

uint16_t triangle_to_sine_modulation [] = {
		0, 11, 28, 47, 66, 80, 87, 85, 73, 55, 33, 14, 2, 2, 19,
		52, 100, 159, 220, 278, 321, 344, 342, 315, 266, 201, 131, 67, 20, 0,
		14, 62, 142, 244, 355, 462, 549, 603, 617, 585, 513, 410, 291, 173, 75,
		14, 2, 43, 135, 268, 426, 587, 731, 836, 886, 875, 801, 676, 515, 343,
		185, 66, 5, 14, 96, 242, 433, 647, 852, 1020, 1130, 1161, 1111, 984, 799,
		581, 361, 173, 46, 0, 46, 179, 386, 638, 903, 1143, 1325, 1423, 1421, 1320,
		1131, 883, 608, 350, 144, 23, 7, 103, 298, 571, 882, 1192, 1455, 1636, 1707,
		1657, 1494, 1238, 926, 602, 313, 104, 5, 34, 192, 457, 797, 1164, 1509, 1782,
		1945, 1974, 1864, 1629, 1302, 929, 564, 259, 61, 1, 90, 319, 659, 1064, 1479,
		1847, 2115, 2245, 2217, 2034, 1722, 1324, 897, 500, 194, 25, 18, 179, 487, 903,
		1370, 1823, 2200, 2445, 2526, 2428, 2164, 1771, 1304, 831, 419, 128, 3, 65, 308,
		700, 1191, 1712, 2190, 2559, 2766, 2781, 2600, 2248, 1775, 1247, 739, 326, 68, 4,
		147, 481, 960, 1521, 2085, 2573, 2917, 3068, 3002, 2729, 2286, 1735, 1154, 627, 230,
		22, 35, 272, 702, 1266, 1889, 2482, 2963, 3264, 3341, 3183, 2810, 2275, 1653, 1033,
		503, 141, 1, 106, 444, 972, 1616, 2289, 2896, 3352, 3592, 3579, 3318, 2841, 2217,
		1534, 889, 375, 67, 11, 220, 667, 1292, 2009, 2718, 3320, 3729, 3890, 3775, 3402,
		2821, 2114, 1383, 730, 251, 17, 62, 385, 942, 1660, 2427, 3128, 3669, 3976, 4004,
		3754, 3258, 2589, 1841, 1118, 521, 131, 0, 144, 537, 1123, 1815, 2516, 3124, 3555,
		3748, 3675, 3351, 2820, 2159, 1459, 819, 326, 48, 19, 242, 682, 1273, 1929, 2557,
		3068, 3390, 3479, 3322, 2944, 2397, 1761, 1122, 571, 182, 7, 68, 352, 817, 1394,
		2000, 2548, 2961, 3182, 3179, 2954, 2541, 1997, 1400, 832, 373, 84, 1, 136, 463,
		935, 1483, 2027, 2490, 2807, 2934, 2853, 2579, 2150, 1625, 1081, 591, 223, 26, 24,
		215, 567, 1029, 1534, 2008, 2384, 2610, 2656, 2514, 2207, 1779, 1289, 806, 396, 116,
		2, 66, 295, 655, 1092, 1543, 1942, 2234, 2378, 2355, 2169, 1847, 1434, 990, 576,
		247, 48, 4, 117, 369, 720, 1119, 1507, 1831, 2044, 2116, 2040, 1825, 1504, 1123,
		733, 390, 138, 12, 25, 171, 428, 756, 1107, 1430, 1679, 1821, 1833, 1718, 1492,
		1187, 847, 518, 246, 66, 0, 55, 219, 466, 759, 1054, 1310, 1489, 1569, 1536,
		1399, 1176, 902, 611, 346, 141, 23, 5, 87, 252, 476, 724, 960, 1150, 1267,
		1297, 1234, 1091, 886, 650, 416, 214, 71, 4, 19, 112, 264, 453, 650, 825,
		954, 1020, 1013, 935, 800, 625, 437, 260, 118, 28, 0, 34, 122, 250, 395,
		536, 653, 728, 753, 725, 647, 533, 398, 263, 144, 55, 7, 4, 42, 112,
		203, 298, 383, 447, 478, 476, 440, 376, 296, 209, 128, 62, 19, 1, 7,
		34, 75, 120, 163, 194, 211, 211, 195, 167, 131, 93, 58, 30, 11, 2,
		0, 2, 5, 5, 0
};
uint16_t triangle_to_square_modulation [] = {
		0, 16, 33, 49, 66, 82, 98, 115, 131, 0, 0, 0, 0, 0, 0,
		0, 0, 279, 295, 312, 328, 345, 361, 377, 394, 0, 0, 0, 0, 0,
		0, 0, 0, 0, 558, 574, 591, 607, 624, 640, 657, 673, 0, 0, 0,
		0, 0, 0, 0, 0, 821, 837, 853, 870, 886, 903, 919, 936, 952, 0,
		0, 0, 0, 0, 0, 0, 0, 1100, 1116, 1132, 1149, 1165, 1182, 1198, 1215,
		0, 0, 0, 0, 0, 0, 0, 0, 0, 1379, 1395, 1412, 1428, 1444, 1461,
		1477, 1494, 0, 0, 0, 0, 0, 0, 0, 0, 1641, 1658, 1674, 1691, 1707,
		1723, 1740, 1756, 1773, 0, 0, 0, 0, 0, 0, 0, 0, 1920, 1937, 1953,
		1970, 1986, 2002, 2019, 2035, 0, 0, 0, 0, 0, 0, 0, 0, 0, 2199,
		2216, 2232, 2249, 2265, 2281, 2298, 2314, 0, 0, 0, 0, 0, 0, 0, 0,
		2462, 2478, 2495, 2511, 2528, 2544, 2560, 2577, 2593, 0, 0, 0, 0, 0, 0,
		0, 0, 2741, 2757, 2774, 2790, 2807, 2823, 2839, 2856, 0, 0, 0, 0, 0,
		0, 0, 0, 3004, 3020, 3036, 3053, 3069, 3086, 3102, 3118, 3135, 0, 0, 0,
		0, 0, 0, 0, 0, 3283, 3299, 3315, 3332, 3348, 3365, 3381, 3397, 0, 0,
		0, 0, 0, 0, 0, 0, 0, 3562, 3578, 3594, 3611, 3627, 3644, 3660, 3676,
		0, 0, 0, 0, 0, 0, 0, 0, 3824, 3841, 3857, 3873, 3890, 3906, 3923,
		3939, 3955, 0, 0, 0, 0, 0, 0, 0, 0, 4087, 4070, 4054, 4038, 4021,
		4005, 3988, 3972, 0, 0, 0, 0, 0, 0, 0, 0, 0, 3808, 3791, 3775,
		3759, 3742, 3726, 3709, 3693, 0, 0, 0, 0, 0, 0, 0, 0, 3545, 3529,
		3512, 3496, 3480, 3463, 3447, 3430, 3414, 0, 0, 0, 0, 0, 0, 0, 0,
		3266, 3250, 3233, 3217, 3201, 3184, 3168, 3151, 0, 0, 0, 0, 0, 0, 0,
		0, 0, 2987, 2971, 2954, 2938, 2921, 2905, 2889, 2872, 0, 0, 0, 0, 0,
		0, 0, 0, 2725, 2708, 2692, 2675, 2659, 2642, 2626, 2610, 0, 0, 0, 0,
		0, 0, 0, 0, 0, 2446, 2429, 2413, 2396, 2380, 2363, 2347, 2331, 0, 0,
		0, 0, 0, 0, 0, 0, 2183, 2166, 2150, 2134, 2117, 2101, 2084, 2068, 2052,
		0, 0, 0, 0, 0, 0, 0, 0, 1904, 1887, 1871, 1855, 1838, 1822, 1805,
		1789, 0, 0, 0, 0, 0, 0, 0, 0, 0, 1625, 1608, 1592, 1576, 1559,
		1543, 1526, 1510, 0, 0, 0, 0, 0, 0, 0, 0, 1362, 1346, 1329, 1313,
		1297, 1280, 1264, 1247, 1231, 0, 0, 0, 0, 0, 0, 0, 0, 1083, 1067,
		1050, 1034, 1018, 1001, 985, 968, 0, 0, 0, 0, 0, 0, 0, 0, 0,
		804, 788, 771, 755, 739, 722, 706, 689, 0, 0, 0, 0, 0, 0, 0,
		0, 542, 525, 509, 492, 476, 460, 443, 427, 410, 0, 0, 0, 0, 0,
		0, 0, 0, 263, 246, 230, 213, 197, 181, 164, 148, 0, 0, 0, 0,
		0, 0, 0, 0, 0
};
uint16_t triangle_to_triangle_modulation [] = {
		0, 2, 8, 18, 32, 49, 71, 97, 126, 136, 131, 123, 110, 93, 73,
		48, 20, 12, 48, 89, 133, 181, 233, 289, 349, 407, 373, 334, 291, 244,
		193, 139, 80, 17, 49, 120, 194, 272, 355, 441, 532, 626, 655, 586, 512,
		435, 354, 269, 180, 87, 10, 111, 215, 324, 437, 554, 674, 799, 927, 877,
		774, 666, 555, 439, 320, 197, 70, 62, 197, 336, 479, 626, 777, 931, 1091,
		1209, 1075, 937, 795, 650, 500, 346, 189, 27, 138, 308, 481, 658, 839, 1025,
		1214, 1407, 1416, 1248, 1076, 900, 720, 536, 348, 156, 39, 239, 443, 651, 862,
		1077, 1297, 1520, 1748, 1599, 1396, 1190, 980, 766, 547, 325, 99, 131, 365, 603,
		845, 1091, 1340, 1594, 1852, 1990, 1757, 1520, 1280, 1035, 787, 534, 278, 18, 247,
		515, 787, 1064, 1344, 1627, 1916, 2207, 2158, 1891, 1620, 1345, 1066, 783, 496, 206,
		89, 387, 690, 996, 1307, 1621, 1939, 2262, 2588, 2302, 1999, 1694, 1386, 1072, 755,
		434, 109, 220, 553, 889, 1230, 1575, 1923, 2276, 2633, 2751, 2420, 2084, 1745, 1401,
		1054, 702, 347, 12, 375, 742, 1114, 1488, 1867, 2251, 2637, 3028, 2879, 2514, 2144,
		1771, 1393, 1011, 625, 235, 158, 555, 957, 1362, 1771, 2185, 2602, 3023, 3380, 2984,
		2583, 2179, 1771, 1359, 943, 523, 100, 328, 760, 1195, 1636, 2079, 2526, 2978, 3433,
		3493, 3062, 2629, 2189, 1748, 1302, 851, 397, 62, 523, 989, 1459, 1933, 2411, 2893,
		3378, 3868, 3582, 3117, 2648, 2176, 1699, 1219, 734, 246, 246, 734, 1219, 1699, 2176,
		2648, 3117, 3582, 3868, 3378, 2893, 2411, 1933, 1459, 989, 523, 62, 397, 851, 1302,
		1748, 2189, 2629, 3062, 3493, 3433, 2978, 2526, 2079, 1636, 1195, 760, 328, 100, 523,
		943, 1359, 1771, 2179, 2583, 2984, 3380, 3023, 2602, 2185, 1771, 1362, 957, 555, 158,
		235, 625, 1011, 1393, 1771, 2144, 2514, 2879, 3028, 2637, 2251, 1867, 1488, 1114, 742,
		375, 12, 347, 702, 1054, 1401, 1745, 2084, 2420, 2751, 2633, 2276, 1923, 1575, 1230,
		889, 553, 220, 109, 434, 755, 1072, 1386, 1694, 1999, 2302, 2588, 2262, 1939, 1621,
		1307, 996, 690, 387, 89, 206, 496, 783, 1066, 1345, 1620, 1891, 2158, 2207, 1916,
		1627, 1344, 1064, 787, 515, 247, 18, 278, 534, 787, 1035, 1280, 1520, 1757, 1990,
		1852, 1594, 1340, 1091, 845, 603, 365, 131, 99, 325, 547, 766, 980, 1190, 1396,
		1599, 1748, 1520, 1297, 1077, 862, 651, 443, 239, 39, 156, 348, 536, 720, 900,
		1076, 1248, 1416, 1407, 1214, 1025, 839, 658, 481, 308, 138, 27, 189, 346, 500,
		650, 795, 937, 1075, 1209, 1091, 931, 777, 626, 479, 336, 197, 62, 70, 197,
		320, 439, 555, 666, 774, 877, 927, 799, 674, 554, 437, 324, 215, 111, 10,
		87, 180, 269, 354, 435, 512, 586, 655, 626, 532, 441, 355, 272, 194, 120,
		49, 17, 80, 139, 193, 244, 291, 334, 373, 407, 349, 289, 233, 181, 133,
		89, 48, 12, 20, 48, 73, 93, 110, 123, 131, 136, 126, 97, 71, 49,
		32, 18, 8, 2, 0
};
uint16_t triangle_to_sawtooth_modulation [] = {
		0, 1, 4, 9, 16, 25, 35, 48, 63, 80, 99, 120, 142, 166, 194,
		222, 253, 6, 24, 44, 66, 91, 116, 144, 175, 206, 240, 276, 314, 354,
		395, 440, 485, 533, 25, 60, 97, 136, 178, 221, 266, 313, 362, 413, 466,
		521, 578, 637, 698, 760, 5, 55, 108, 162, 218, 277, 337, 400, 464, 530,
		598, 668, 741, 814, 890, 969, 1048, 31, 98, 168, 239, 313, 389, 466, 545,
		626, 710, 795, 882, 972, 1063, 1156, 1252, 1348, 69, 154, 241, 329, 420, 512,
		607, 704, 802, 902, 1005, 1109, 1216, 1324, 1434, 1547, 20, 119, 222, 325, 431,
		539, 648, 760, 874, 990, 1107, 1227, 1348, 1472, 1597, 1724, 1854, 66, 183, 301,
		422, 545, 670, 797, 926, 1057, 1189, 1324, 1461, 1600, 1741, 1883, 2027, 2174, 124,
		258, 394, 532, 672, 814, 958, 1104, 1252, 1402, 1553, 1708, 1863, 2021, 2180, 2343,
		44, 194, 345, 498, 654, 811, 970, 1131, 1294, 1460, 1626, 1795, 1966, 2139, 2315,
		2491, 2670, 110, 276, 445, 615, 788, 962, 1138, 1316, 1497, 1679, 1863, 2049, 2237,
		2427, 2620, 2813, 6, 187, 371, 557, 744, 934, 1125, 1319, 1514, 1711, 1911, 2112,
		2316, 2521, 2728, 2937, 3148, 79, 278, 478, 681, 885, 1092, 1301, 1511, 1724, 1938,
		2155, 2374, 2594, 2816, 3040, 3267, 3496, 164, 380, 598, 817, 1040, 1264, 1489, 1716,
		1946, 2177, 2412, 2647, 2885, 3124, 3365, 3610, 31, 262, 494, 729, 967, 1206, 1447,
		1689, 1934, 2181, 2430, 2681, 2933, 3188, 3445, 3703, 3964, 123, 367, 609, 850, 1088,
		1324, 1558, 1791, 2021, 2250, 2476, 2700, 2923, 3144, 3363, 3579, 3793, 198, 426, 651,
		874, 1095, 1314, 1532, 1747, 1960, 2171, 2380, 2587, 2794, 2996, 3198, 3398, 49, 262,
		472, 680, 886, 1089, 1292, 1492, 1690, 1886, 2080, 2273, 2463, 2651, 2837, 3021, 3204,
		118, 313, 505, 696, 885, 1072, 1257, 1440, 1621, 1799, 1977, 2152, 2325, 2496, 2665,
		2833, 2998, 174, 351, 527, 701, 872, 1042, 1210, 1375, 1540, 1701, 1861, 2019, 2175,
		2329, 2481, 2631, 55, 217, 377, 536, 693, 847, 1000, 1150, 1299, 1446, 1590, 1733,
		1874, 2013, 2150, 2284, 2418, 103, 249, 392, 533, 672, 810, 945, 1079, 1210, 1340,
		1467, 1593, 1717, 1838, 1958, 2075, 9, 139, 267, 393, 517, 640, 760, 879, 995,
		1109, 1222, 1332, 1441, 1548, 1652, 1754, 1854, 50, 163, 274, 383, 490, 595, 698,
		799, 899, 996, 1092, 1184, 1276, 1366, 1452, 1539, 1621, 78, 174, 268, 360, 450,
		538, 624, 708, 790, 870, 949, 1024, 1099, 1171, 1241, 1310, 14, 94, 173, 250,
		325, 398, 469, 537, 605, 670, 732, 793, 852, 910, 964, 1018, 1069, 35, 98,
		160, 220, 277, 333, 387, 438, 488, 536, 582, 626, 668, 708, 745, 782, 816,
		44, 90, 134, 177, 218, 256, 293, 327, 360, 391, 419, 446, 471, 494, 514,
		533, 9, 40, 69, 97, 122, 146, 167, 187, 204, 219, 233, 245, 254, 262,
		268, 271, 273, 10, 24, 36, 47, 55, 61, 65, 68, 68, 67, 63, 57,
		50, 40, 29, 15, 0
};

uint16_t sawtooth_to_sine_modulation [] = {
		0, 5, 13, 24, 33, 40, 43, 42, 37, 28, 17, 7, 1, 1, 9,
		26, 50, 80, 111, 139, 160, 172, 172, 158, 133, 101, 65, 33, 10, 0,
		7, 31, 71, 122, 178, 231, 274, 302, 308, 292, 256, 205, 145, 86, 38,
		7, 1, 21, 67, 134, 213, 294, 366, 418, 443, 437, 401, 338, 257, 171,
		93, 33, 3, 7, 48, 121, 217, 323, 426, 510, 564, 581, 556, 492, 399,
		290, 181, 87, 23, 0, 23, 90, 193, 319, 451, 572, 663, 711, 710, 659,
		566, 441, 304, 175, 72, 11, 4, 51, 149, 285, 441, 596, 728, 818, 853,
		829, 747, 619, 463, 301, 157, 52, 2, 17, 96, 229, 398, 582, 754, 891,
		973, 987, 932, 814, 651, 465, 282, 130, 31, 0, 45, 159, 329, 532, 740,
		923, 1057, 1122, 1108, 1018, 861, 662, 448, 250, 97, 12, 9, 89, 244, 452,
		685, 912, 1100, 1223, 1263, 1214, 1082, 885, 652, 416, 209, 64, 1, 32, 154,
		350, 595, 856, 1095, 1280, 1383, 1390, 1301, 1125, 887, 623, 370, 163, 34, 2,
		74, 240, 480, 760, 1042, 1286, 1458, 1534, 1501, 1365, 1143, 867, 577, 314, 115,
		11, 18, 136, 351, 633, 944, 1241, 1482, 1632, 1670, 1591, 1406, 1138, 827, 516,
		251, 71, 0, 53, 222, 486, 808, 1145, 1448, 1676, 1795, 1790, 1659, 1421, 1109,
		767, 444, 187, 33, 6, 110, 333, 646, 1004, 1359, 1660, 1865, 1945, 1888, 1700,
		1411, 1057, 692, 365, 126, 8, 31, 193, 471, 830, 1219, 1583, 1872, 2044, 2075,
		1962, 1716, 1375, 985, 603, 283, 72, 0, 80, 301, 636, 1036, 1448, 1812, 2079,
		2210, 2184, 2007, 1703, 1315, 896, 507, 203, 30, 12, 155, 439, 827, 1263, 1689,
		2043, 2276, 2354, 2267, 2026, 1663, 1232, 792, 406, 130, 5, 49, 259, 606, 1042,
		1508, 1937, 2269, 2460, 2478, 2322, 2014, 1596, 1129, 677, 306, 69, 1, 114, 393,
		800, 1280, 1765, 2187, 2488, 2623, 2573, 2346, 1973, 1504, 1009, 557, 212, 25, 23,
		210, 558, 1023, 1538, 2032, 2435, 2690, 2763, 2640, 2338, 1902, 1390, 877, 436, 129,
		2, 74, 337, 755, 1270, 1812, 2303, 2675, 2875, 2874, 2673, 2298, 1803, 1257, 738,
		320, 63, 5, 156, 497, 980, 1540, 2096, 2572, 2901, 3035, 2957, 2674, 2227, 1680,
		1108, 595, 214, 18, 39, 273, 691, 1235, 1827, 2388, 2835, 3109, 3167, 3003, 2638,
		2125, 1534, 950, 456, 123, 0, 106, 426, 918, 1513, 2130, 2680, 3086, 3292, 3266,
		3015, 2569, 1994, 1370, 786, 325, 54, 12, 208, 614, 1176, 1814, 2441, 2967, 3319,
		3447, 3331, 2989, 2466, 1838, 1193, 623, 210, 12, 59, 348, 838, 1461, 2132, 2756,
		3244, 3528, 3568, 3357, 2926, 2332, 1661, 1009, 467, 114, 0, 144, 527, 1096, 1773,
		2462, 3067, 3503, 3709, 3653, 3345, 2825, 2168, 1469, 823, 324, 44, 24, 269, 745,
		1387, 2104, 2798, 3371, 3741, 3855, 3698, 3290, 2690, 1982, 1264, 641, 201, 6, 87,
		434, 1000, 1705, 2452, 3135, 3659, 3949, 3965, 3702, 3198, 2524, 1774, 1056, 470, 102,
		4, 192, 641, 1289, 0
};
uint16_t sawtooth_to_square_modulation [] = {
		0, 8, 16, 25, 33, 41, 49, 57, 66, 0, 0, 0, 0, 0, 0,
		0, 0, 140, 148, 156, 164, 172, 181, 189, 197, 0, 0, 0, 0, 0,
		0, 0, 0, 0, 279, 287, 295, 304, 312, 320, 328, 336, 0, 0, 0,
		0, 0, 0, 0, 0, 410, 419, 427, 435, 443, 451, 460, 468, 476, 0,
		0, 0, 0, 0, 0, 0, 0, 550, 558, 566, 574, 583, 591, 599, 607,
		0, 0, 0, 0, 0, 0, 0, 0, 0, 689, 698, 706, 714, 722, 730,
		739, 747, 0, 0, 0, 0, 0, 0, 0, 0, 821, 829, 837, 845, 853,
		862, 870, 878, 886, 0, 0, 0, 0, 0, 0, 0, 0, 960, 968, 977,
		985, 993, 1001, 1009, 1018, 0, 0, 0, 0, 0, 0, 0, 0, 0, 1100,
		1108, 1116, 1124, 1132, 1141, 1149, 1157, 0, 0, 0, 0, 0, 0, 0, 0,
		1231, 1239, 1247, 1256, 1264, 1272, 1280, 1288, 1297, 0, 0, 0, 0, 0, 0,
		0, 0, 1370, 1379, 1387, 1395, 1403, 1412, 1420, 1428, 0, 0, 0, 0, 0,
		0, 0, 0, 1502, 1510, 1518, 1526, 1535, 1543, 1551, 1559, 1567, 0, 0, 0,
		0, 0, 0, 0, 0, 1641, 1649, 1658, 1666, 1674, 1682, 1691, 1699, 0, 0,
		0, 0, 0, 0, 0, 0, 0, 1781, 1789, 1797, 1805, 1814, 1822, 1830, 1838,
		0, 0, 0, 0, 0, 0, 0, 0, 1912, 1920, 1929, 1937, 1945, 1953, 1961,
		1970, 1978, 0, 0, 0, 0, 0, 0, 0, 0, 2052, 2060, 2068, 2076, 2084,
		2093, 2101, 2109, 0, 0, 0, 0, 0, 0, 0, 0, 0, 2191, 2199, 2208,
		2216, 2224, 2232, 2240, 2249, 0, 0, 0, 0, 0, 0, 0, 0, 2322, 2331,
		2339, 2347, 2355, 2363, 2372, 2380, 2388, 0, 0, 0, 0, 0, 0, 0, 0,
		2462, 2470, 2478, 2487, 2495, 2503, 2511, 2519, 0, 0, 0, 0, 0, 0, 0,
		0, 0, 2601, 2610, 2618, 2626, 2634, 2642, 2651, 2659, 0, 0, 0, 0, 0,
		0, 0, 0, 2733, 2741, 2749, 2757, 2766, 2774, 2782, 2790, 0, 0, 0, 0,
		0, 0, 0, 0, 0, 2872, 2880, 2889, 2897, 2905, 2913, 2921, 2930, 0, 0,
		0, 0, 0, 0, 0, 0, 3004, 3012, 3020, 3028, 3036, 3045, 3053, 3061, 3069,
		0, 0, 0, 0, 0, 0, 0, 0, 3143, 3151, 3159, 3168, 3176, 3184, 3192,
		3201, 0, 0, 0, 0, 0, 0, 0, 0, 0, 3283, 3291, 3299, 3307, 3315,
		3324, 3332, 3340, 0, 0, 0, 0, 0, 0, 0, 0, 3414, 3422, 3430, 3438,
		3447, 3455, 3463, 3471, 3480, 0, 0, 0, 0, 0, 0, 0, 0, 3553, 3562,
		3570, 3578, 3586, 3594, 3603, 3611, 0, 0, 0, 0, 0, 0, 0, 0, 0,
		3693, 3701, 3709, 3718, 3726, 3734, 3742, 3750, 0, 0, 0, 0, 0, 0, 0,
		0, 3824, 3832, 3841, 3849, 3857, 3865, 3873, 3882, 3890, 0, 0, 0, 0, 0,
		0, 0, 0, 3964, 3972, 3980, 3988, 3997, 4005, 4013, 4021, 0, 0, 0, 0,
		0, 0, 0, 0, 0
};
uint16_t sawtooth_to_triangle_modulation [] = {
		0, 1, 4, 9, 16, 25, 35, 48, 63, 68, 65, 61, 55, 47, 36,
		24, 10, 6, 24, 44, 66, 90, 117, 145, 174, 204, 186, 167, 146, 122,
		97, 69, 40, 9, 25, 60, 97, 136, 178, 221, 266, 312, 328, 293, 256,
		217, 177, 135, 90, 43, 5, 55, 108, 162, 218, 277, 337, 400, 464, 438,
		387, 333, 277, 220, 160, 98, 35, 31, 98, 168, 239, 313, 389, 466, 545,
		604, 538, 469, 398, 325, 250, 173, 94, 14, 69, 154, 241, 329, 420, 512,
		607, 704, 708, 624, 538, 450, 360, 268, 174, 78, 20, 120, 221, 325, 431,
		539, 649, 760, 874, 799, 699, 595, 490, 383, 274, 163, 50, 65, 182, 302,
		422, 545, 670, 797, 926, 995, 879, 760, 640, 518, 393, 267, 139, 9, 124,
		258, 394, 532, 671, 814, 958, 1104, 1079, 946, 810, 672, 533, 391, 248, 103,
		44, 194, 345, 498, 653, 811, 970, 1130, 1294, 1151, 1000, 847, 693, 536, 378,
		217, 55, 110, 276, 445, 615, 787, 962, 1138, 1316, 1376, 1210, 1042, 873, 701,
		527, 351, 174, 6, 188, 371, 557, 744, 934, 1125, 1318, 1513, 1440, 1257, 1072,
		885, 696, 505, 313, 118, 79, 277, 479, 681, 885, 1092, 1301, 1512, 1690, 1492,
		1291, 1090, 886, 680, 472, 261, 50, 164, 380, 598, 818, 1040, 1263, 1489, 1716,
		1746, 1532, 1314, 1095, 874, 651, 426, 199, 31, 262, 495, 730, 967, 1206, 1446,
		1690, 1935, 1791, 1559, 1324, 1088, 850, 609, 367, 123, 123, 372, 622, 873, 1128,
		1384, 1642, 1902, 2070, 1822, 1574, 1322, 1068, 813, 555, 296, 35, 228, 493, 761,
		1030, 1301, 1575, 1849, 2127, 2108, 1843, 1576, 1307, 1037, 764, 490, 213, 65, 346,
		628, 912, 1198, 1487, 1778, 2070, 2364, 2132, 1850, 1567, 1281, 993, 703, 412, 118,
		177, 475, 775, 1077, 1380, 1685, 1993, 2302, 2442, 2145, 1846, 1544, 1242, 937, 630,
		321, 10, 302, 617, 934, 1252, 1573, 1896, 2220, 2547, 2459, 2145, 1828, 1511, 1190,
		868, 545, 218, 109, 440, 771, 1105, 1441, 1779, 2118, 2460, 2793, 2464, 2132, 1799,
		1464, 1127, 787, 446, 104, 242, 589, 938, 1289, 1642, 1997, 2353, 2712, 2802, 2456,
		2107, 1758, 1405, 1050, 694, 336, 24, 386, 751, 1117, 1484, 1855, 2227, 2601, 2977,
		2800, 2436, 2071, 1704, 1334, 962, 589, 214, 163, 543, 924, 1308, 1693, 2080, 2469,
		2861, 3164, 2785, 2404, 2021, 1637, 1251, 862, 471, 78, 316, 712, 1111, 1511, 1913,
		2318, 2724, 3133, 3153, 2758, 2360, 1960, 1558, 1154, 749, 341, 68, 480, 894, 1309,
		1727, 2146, 2567, 2991, 3417, 3131, 2718, 2303, 1886, 1468, 1047, 624, 199, 228, 657,
		1087, 1520, 1955, 2392, 2830, 3271, 3524, 3096, 2667, 2234, 1801, 1364, 926, 487, 44,
		400, 846, 1293, 1743, 2196, 2649, 3104, 3562, 3496, 3049, 2602, 2153, 1702, 1249, 793,
		336, 122, 584, 1047, 1511, 1979, 2447, 2919, 3392, 3866, 3453, 2990, 2525, 2060, 1592,
		1121, 649, 175, 302, 780, 1261, 1742, 2226, 2713, 3201, 3691, 3876, 3399, 2919, 2437,
		1954, 1468, 981, 491, 0
};
uint16_t sawtooth_to_sawtooth_modulation [] = {
		0, 0, 2, 5, 8, 12, 18, 24, 32, 40, 49, 60, 71, 84, 97,
		111, 126, 3, 12, 22, 33, 45, 58, 72, 87, 103, 120, 138, 157, 177,
		198, 219, 243, 267, 12, 30, 48, 68, 89, 110, 133, 156, 181, 207, 233,
		260, 289, 319, 349, 380, 3, 28, 54, 81, 109, 138, 169, 200, 232, 265,
		299, 334, 370, 407, 445, 484, 525, 15, 49, 84, 120, 157, 194, 233, 272,
		313, 355, 398, 441, 486, 532, 578, 626, 674, 34, 77, 120, 165, 210, 256,
		304, 352, 401, 451, 502, 555, 608, 662, 717, 773, 10, 60, 111, 163, 215,
		269, 324, 380, 437, 494, 554, 613, 674, 736, 799, 863, 927, 33, 91, 151,
		211, 273, 335, 398, 463, 528, 595, 662, 730, 800, 870, 941, 1013, 1087, 62,
		129, 197, 266, 336, 407, 479, 552, 626, 701, 777, 854, 931, 1010, 1091, 1172,
		22, 97, 172, 249, 327, 405, 485, 565, 647, 730, 813, 897, 983, 1070, 1157,
		1246, 1335, 55, 138, 223, 308, 394, 481, 569, 658, 748, 839, 932, 1025, 1119,
		1214, 1309, 1407, 3, 94, 186, 278, 372, 467, 562, 659, 757, 856, 955, 1056,
		1158, 1260, 1364, 1469, 1574, 39, 139, 239, 341, 443, 546, 651, 756, 862, 969,
		1077, 1187, 1297, 1408, 1520, 1633, 1748, 82, 190, 299, 409, 520, 632, 745, 858,
		973, 1089, 1206, 1324, 1442, 1562, 1683, 1805, 15, 131, 247, 365, 484, 603, 723,
		845, 967, 1091, 1215, 1340, 1467, 1594, 1723, 1852, 1982, 62, 186, 311, 437, 564,
		692, 821, 951, 1082, 1214, 1347, 1481, 1616, 1752, 1888, 2027, 2165, 114, 247, 381,
		515, 651, 787, 925, 1064, 1203, 1344, 1485, 1627, 1772, 1916, 2061, 2207, 32, 173,
		314, 456, 599, 743, 889, 1035, 1182, 1330, 1479, 1630, 1781, 1933, 2085, 2240, 2395,
		89, 238, 387, 538, 690, 843, 996, 1151, 1307, 1463, 1621, 1780, 1939, 2100, 2262,
		2425, 2588, 151, 308, 467, 627, 787, 948, 1110, 1273, 1438, 1603, 1769, 1937, 2105,
		2274, 2444, 2616, 55, 220, 385, 553, 721, 889, 1059, 1230, 1402, 1575, 1749, 1923,
		2099, 2276, 2454, 2633, 2812, 121, 295, 469, 644, 821, 998, 1176, 1357, 1537, 1718,
		1900, 2084, 2269, 2454, 2640, 2827, 12, 193, 375, 558, 742, 927, 1114, 1301, 1488,
		1677, 1867, 2059, 2251, 2443, 2637, 2832, 3028, 82, 272, 462, 654, 846, 1040, 1235,
		1430, 1627, 1824, 2023, 2222, 2423, 2625, 2827, 3031, 3235, 158, 356, 555, 756, 957,
		1159, 1362, 1566, 1771, 1978, 2185, 2393, 2602, 2811, 3023, 3235, 34, 240, 446, 655,
		864, 1073, 1284, 1495, 1709, 1922, 2137, 2352, 2569, 2788, 3006, 3225, 3445, 114, 328,
		544, 760, 977, 1195, 1415, 1636, 1857, 2079, 2302, 2526, 2752, 2978, 3205, 3433, 3663,
		200, 423, 647, 872, 1097, 1325, 1553, 1781, 2011, 2242, 2473, 2707, 2940, 3175, 3411,
		3647, 62, 292, 523, 756, 989, 1224, 1459, 1696, 1933, 2171, 2411, 2651, 2893, 3135,
		3378, 3623, 3868, 151, 390, 630, 871, 1114, 1357, 1600, 1845, 2091, 2339, 2587, 2835,
		3085, 3336, 3589, 3841, 0
};

uint8_t selected_waveform = 0;
// Utils
uint32_t i = 0, j = 0;
/* USER CODE END PV */

void SystemClock_Config(void);
static void MX_GPIO_Init(void);
static void MX_DMA_Init(void);
static void MX_UART4_Init(void);
static void MX_USART3_UART_Init(void);
static void MX_TIM2_Init(void);
static void MX_TIM1_Init(void);
static void MX_DAC_Init(void);
static void MX_TIM6_Init(void);

int main(void)
{

  /* MCU Configuration--------------------------------------------------------*/

  /* Reset of all peripherals, Initializes the Flash interface and the Systick. */
	HAL_Init();

  /* Configure the system clock */
  SystemClock_Config();

  /* Initialize all configured peripherals */
  MX_GPIO_Init();
  MX_DMA_Init();
  MX_UART4_Init();
  MX_USART3_UART_Init();
  MX_TIM2_Init();
  MX_TIM1_Init();
  MX_DAC_Init();
  MX_TIM6_Init();
  /* USER CODE BEGIN 2 */
  HAL_TIM_Base_Start(&htim1);
  HAL_UART_Receive_DMA(&huart4, rx_buffer, sizeof(rx_buffer)/sizeof(char));

  ID = readID();
  HAL_Delay(100);
  tft_init(ID);
  setRotation(3);

  // LCD
  fillScreen((11)&BLUE | (((16)*2)<<5)&GREEN |  ((26)<<(5+6))&RED );
  fillRect(20 , 80, 280, 120, BLUE_LEV(10) | GREEN_LEV(11) | RED_LEV(17));		// Color de tablero
  fillRect(20 , 20, 280, 50,BLUE_LEV(2) | GREEN_LEV(2) | RED_LEV(2));			// Color de señales

  // PIANO
  fillRect(65 , 205, 190, 35,WHITE);
  fillRect(85 , 205, 10 ,22,BLACK);
  fillRect(115 , 205, 10 ,22,BLACK);
  fillRect(165 , 205, 10 ,22,BLACK);
  fillRect(195 , 205, 10 ,22,BLACK);
  fillRect(225 , 205, 10 ,22,BLACK);

  // CAJAS DE VOLUMEN
  	  // HORIZONTALES
  fillRect(130 , 95, 152, 3,BLACK);
  fillRect(130 , 112, 152, 3,BLACK);
  fillRect(130 , 130, 152, 3,BLACK);
  fillRect(130 , 147, 152, 3,BLACK);
  fillRect(130 , 165, 152, 3,BLACK);
  fillRect(130 , 182, 152, 3,BLACK);

  	  // VERTICALES
  for(i = 0; i < 5; i++){
  	fillRect(130+(i*38) , 95, 3, 20,BLACK);
  	fillRect(130+(i*38) , 130, 3, 20,BLACK);
  	fillRect(130+(i*38) , 165, 3, 20,BLACK);
  }

  // Sine
  fillCircle(50, 44, 10 , WHITE);
  fillCircle(50, 48, 10 , BLACK);

  fillCircle(70, 42, 10 , WHITE);
  fillCircle(70, 38, 10 , BLACK);

  // Square
  fillRect(97 ,60, 17, 3,WHITE);
  fillRect(117 ,26, 20, 3,WHITE);
  fillRect(134 ,60, 17, 3,WHITE);

  fillRect(114 ,26, 3, 37,WHITE);
  fillRect(134 ,26, 3, 34,WHITE);
  fillRect(97 ,45, 3, 15,WHITE);

  // Triangular
  fillTriangle(160, 44, 190, 44, 175, 25, WHITE);
  fillTriangle(160+3, 44, 190-3, 44, 175, 25+3, BLACK);
  fillTriangle(190, 44, 220, 44, 205, 63, WHITE);
  fillTriangle(190+3, 44, 220-3, 44, 205, 63-3, BLACK);

  // Sawtooth
  fillTriangle(230, 63, 275, 63, 275, 25, WHITE);
  fillTriangle(230, 63+3, 275-2, 63, 275-2, 25+3, BLACK);

  // Modulations
  // Square
  fillRect(50-15 ,105, 17, 3,WHITE);
  fillRect(50 ,90, 3, 17,WHITE);
  fillRect(50 ,90, 17, 3,WHITE);
  fillRect(67 ,90, 3, 17,WHITE);
  fillRect(50+17 ,105, 17, 3,WHITE);

  // Triangle
  fillTriangle(50-10, 145-2, 70-10, 145-2, 60-10, 135-2, WHITE);
  fillTriangle(50+3-10, 145-2, 70-3-10, 145-2, 60-10, 135+3-2,  BLUE_LEV(10) | GREEN_LEV(11) | RED_LEV(17));

  fillTriangle(68-10, 145-2, 90-10, 145-2, 80-10, 155-2, WHITE);
  fillTriangle(68+3-10, 145-2, 90-3-10, 145-2, 80-10, 155-3-2, BLUE_LEV(10) | GREEN_LEV(11) | RED_LEV(17));

  // Sawtooth

  fillTriangle(50, 190, 80, 190, 80, 165, WHITE);
  fillTriangle(50+3, 190, 80-3, 190, 80-3, 170, BLUE_LEV(10) | GREEN_LEV(11) | RED_LEV(17));

//  fillTriangle(160+3, 44, 190-3, 44, 175, 25+3, BLACK);
//  fillTriangle(190, 44, 220, 44, 205, 63, WHITE);
//  fillTriangle(190+3, 44, 220-3, 44, 205, 63-3, BLACK);

  HAL_TIM_Base_Start(&htim6);

  /* USER CODE END 2 */

  /* Infinite loop */
	while (1) {

    /* USER CODE BEGIN 3 */
		  if(!EXT_BTN_1_state){
			  current_envelope_selection++;
			  if(current_envelope_selection < 5){
				  for (i = 0; i < current_envelope_selection; i++) fillRect(133+(i*38), 168, 35,14,BLUE);
			  }else{
				  for (i = 0; i < 4; i++) fillRect(133+(i*38), 168, 35,14,BLUE_LEV(10) | GREEN_LEV(11) | RED_LEV(17));
				  current_envelope_selection = 0;
			  }
			  selected_waveform = current_envelope_selection;
			  EXT_BTN_1_state = true;
		  }
		  if(!EXT_BTN_2_state){
			  current_fm_selection++;
			  if(current_fm_selection < 5){
				  for (i = 0; i < current_fm_selection; i++) fillRect(133+(i*38), 133, 35,14,BLUE);
			  }else{
				  for (i = 0; i < 4; i++) fillRect(133+(i*38), 133, 35,14,BLUE_LEV(10) | GREEN_LEV(11) | RED_LEV(17));
				  current_fm_selection = 0;
			  }
			  selected_waveform = current_fm_selection + 4;
			  EXT_BTN_2_state = true;
		  }
		  if(!EXT_BTN_3_state){
			  current_am_selection++;
			  if(current_am_selection < 5){
				  for (i = 0; i < current_am_selection; i++) fillRect(133+(i*38), 98, 35,14,BLUE);
			  }else{
			  		for (i = 0; i < 4; i++) fillRect(133+(i*38), 98, 35,14,BLUE_LEV(10) | GREEN_LEV(11) | RED_LEV(17));
			  		current_am_selection = 0;
			  }
			  selected_waveform = current_am_selection + 8;
			  EXT_BTN_3_state = true;
		  }
		  if(!EXT_BTN_4_state){
			  current_signal_selection++;
			  if(current_signal_selection < 5){
				  for (i=1; i <= current_signal_selection; i++){
					  fillRect(24+((i-2)*65), 22, 3,46,BLACK);
					  fillRect(24+((i-1)*65), 22, 3,46,YELLOW);
					  fillRect(89+((i-1)*65), 22, 3,46,YELLOW);
					  fillRect(24+((i-2)*65), 22, 65,3,BLACK);
					  fillRect(24+((i-2)*65), 65, 65,3,BLACK);
					  fillRect(24+((i-1)*65), 22, 65,3,YELLOW);
					  fillRect(24+((i-1)*65), 65, 65,3,YELLOW);
				  }
			  }else{
				  fillRect(219, 22, 3,46,BLACK);
				  fillRect(284, 22, 3,46,BLACK);
				  fillRect(24, 22, 3,46,YELLOW);
				  fillRect(89, 22, 3,46,YELLOW);
				  fillRect(219, 22, 65,3,BLACK);
				  fillRect(219, 65, 65,3,BLACK);
				  fillRect(24, 22, 65,3,YELLOW);
				  fillRect(24, 65, 65,3,YELLOW);
				  current_signal_selection = 1;
			  }
			  selected_waveform = current_signal_selection + 12;
			  EXT_BTN_4_state = true;
		  }
	}
  /* USER CODE END 3 */
}

void SystemClock_Config(void)
{
  RCC_OscInitTypeDef RCC_OscInitStruct = {0};
  RCC_ClkInitTypeDef RCC_ClkInitStruct = {0};
  RCC_PeriphCLKInitTypeDef PeriphClkInitStruct = {0};

  /** Configure LSE Drive Capability
  */
  HAL_PWR_EnableBkUpAccess();
  /** Configure the main internal regulator output voltage
  */
  __HAL_RCC_PWR_CLK_ENABLE();
  __HAL_PWR_VOLTAGESCALING_CONFIG(PWR_REGULATOR_VOLTAGE_SCALE3);
  /** Initializes the RCC Oscillators according to the specified parameters
  * in the RCC_OscInitTypeDef structure.
  */
  RCC_OscInitStruct.OscillatorType = RCC_OSCILLATORTYPE_HSI;
  RCC_OscInitStruct.HSIState = RCC_HSI_ON;
  RCC_OscInitStruct.HSICalibrationValue = RCC_HSICALIBRATION_DEFAULT;
  RCC_OscInitStruct.PLL.PLLState = RCC_PLL_ON;
  RCC_OscInitStruct.PLL.PLLSource = RCC_PLLSOURCE_HSI;
  RCC_OscInitStruct.PLL.PLLM = 8;
  RCC_OscInitStruct.PLL.PLLN = 144;
  RCC_OscInitStruct.PLL.PLLP = RCC_PLLP_DIV2;
  RCC_OscInitStruct.PLL.PLLQ = 4;
  if (HAL_RCC_OscConfig(&RCC_OscInitStruct) != HAL_OK)
  {
    Error_Handler();
  }
  /** Initializes the CPU, AHB and APB buses clocks
  */
  RCC_ClkInitStruct.ClockType = RCC_CLOCKTYPE_HCLK|RCC_CLOCKTYPE_SYSCLK
                              |RCC_CLOCKTYPE_PCLK1|RCC_CLOCKTYPE_PCLK2;
  RCC_ClkInitStruct.SYSCLKSource = RCC_SYSCLKSOURCE_PLLCLK;
  RCC_ClkInitStruct.AHBCLKDivider = RCC_SYSCLK_DIV1;
  RCC_ClkInitStruct.APB1CLKDivider = RCC_HCLK_DIV8;
  RCC_ClkInitStruct.APB2CLKDivider = RCC_HCLK_DIV4;

  if (HAL_RCC_ClockConfig(&RCC_ClkInitStruct, FLASH_LATENCY_4) != HAL_OK)
  {
    Error_Handler();
  }
  PeriphClkInitStruct.PeriphClockSelection = RCC_PERIPHCLK_USART3|RCC_PERIPHCLK_UART4;
  PeriphClkInitStruct.Usart3ClockSelection = RCC_USART3CLKSOURCE_PCLK1;
  PeriphClkInitStruct.Uart4ClockSelection = RCC_UART4CLKSOURCE_PCLK1;
  if (HAL_RCCEx_PeriphCLKConfig(&PeriphClkInitStruct) != HAL_OK)
  {
    Error_Handler();
  }
}

static void MX_DAC_Init(void)
{

  DAC_ChannelConfTypeDef sConfig = {0};

  /** DAC Initialization
  */
  hdac.Instance = DAC;
  if (HAL_DAC_Init(&hdac) != HAL_OK)
  {
    Error_Handler();
  }
  /** DAC channel OUT1 config
  */
  sConfig.DAC_Trigger = DAC_TRIGGER_T6_TRGO;
  sConfig.DAC_OutputBuffer = DAC_OUTPUTBUFFER_ENABLE;
  if (HAL_DAC_ConfigChannel(&hdac, &sConfig, DAC_CHANNEL_1) != HAL_OK)
  {
    Error_Handler();
  }
  /** DAC channel OUT2 config
  */
  if (HAL_DAC_ConfigChannel(&hdac, &sConfig, DAC_CHANNEL_2) != HAL_OK)
  {
    Error_Handler();
  }

}

static void MX_TIM1_Init(void)
{

  TIM_ClockConfigTypeDef sClockSourceConfig = {0};
  TIM_MasterConfigTypeDef sMasterConfig = {0};

  htim1.Instance = TIM1;
  htim1.Init.Prescaler = 72-1;
  htim1.Init.CounterMode = TIM_COUNTERMODE_UP;
  htim1.Init.Period = 0xffff-1;
  htim1.Init.ClockDivision = TIM_CLOCKDIVISION_DIV1;
  htim1.Init.RepetitionCounter = 0;
  htim1.Init.AutoReloadPreload = TIM_AUTORELOAD_PRELOAD_DISABLE;
  if (HAL_TIM_Base_Init(&htim1) != HAL_OK)
  {
    Error_Handler();
  }
  sClockSourceConfig.ClockSource = TIM_CLOCKSOURCE_INTERNAL;
  if (HAL_TIM_ConfigClockSource(&htim1, &sClockSourceConfig) != HAL_OK)
  {
    Error_Handler();
  }
  sMasterConfig.MasterOutputTrigger = TIM_TRGO_RESET;
  sMasterConfig.MasterOutputTrigger2 = TIM_TRGO2_RESET;
  sMasterConfig.MasterSlaveMode = TIM_MASTERSLAVEMODE_DISABLE;
  if (HAL_TIMEx_MasterConfigSynchronization(&htim1, &sMasterConfig) != HAL_OK)
  {
    Error_Handler();
  }

}

static void MX_TIM2_Init(void)
{

  TIM_ClockConfigTypeDef sClockSourceConfig = {0};
  TIM_MasterConfigTypeDef sMasterConfig = {0};

  htim2.Instance = TIM2;
  htim2.Init.Prescaler = 36000-1;
  htim2.Init.CounterMode = TIM_COUNTERMODE_UP;
  htim2.Init.Period = 40-1;
  htim2.Init.ClockDivision = TIM_CLOCKDIVISION_DIV1;
  htim2.Init.AutoReloadPreload = TIM_AUTORELOAD_PRELOAD_DISABLE;
  if (HAL_TIM_Base_Init(&htim2) != HAL_OK)
  {
    Error_Handler();
  }
  sClockSourceConfig.ClockSource = TIM_CLOCKSOURCE_INTERNAL;
  if (HAL_TIM_ConfigClockSource(&htim2, &sClockSourceConfig) != HAL_OK)
  {
    Error_Handler();
  }
  sMasterConfig.MasterOutputTrigger = TIM_TRGO_RESET;
  sMasterConfig.MasterSlaveMode = TIM_MASTERSLAVEMODE_DISABLE;
  if (HAL_TIMEx_MasterConfigSynchronization(&htim2, &sMasterConfig) != HAL_OK)
  {
    Error_Handler();
  }

}

static void MX_TIM6_Init(void)
{

  TIM_MasterConfigTypeDef sMasterConfig = {0};

  htim6.Instance = TIM6;
  htim6.Init.Prescaler = 55-1;
  htim6.Init.CounterMode = TIM_COUNTERMODE_UP;
  htim6.Init.Period = 15-1;
  htim6.Init.AutoReloadPreload = TIM_AUTORELOAD_PRELOAD_DISABLE;
  if (HAL_TIM_Base_Init(&htim6) != HAL_OK)
  {
    Error_Handler();
  }
  sMasterConfig.MasterOutputTrigger = TIM_TRGO_UPDATE;
  sMasterConfig.MasterSlaveMode = TIM_MASTERSLAVEMODE_DISABLE;
  if (HAL_TIMEx_MasterConfigSynchronization(&htim6, &sMasterConfig) != HAL_OK)
  {
    Error_Handler();
  }

}

static void MX_UART4_Init(void)
{

  huart4.Instance = UART4;
  huart4.Init.BaudRate = 31250;
  huart4.Init.WordLength = UART_WORDLENGTH_8B;
  huart4.Init.StopBits = UART_STOPBITS_1;
  huart4.Init.Parity = UART_PARITY_NONE;
  huart4.Init.Mode = UART_MODE_TX_RX;
  huart4.Init.HwFlowCtl = UART_HWCONTROL_NONE;
  huart4.Init.OverSampling = UART_OVERSAMPLING_16;
  huart4.Init.OneBitSampling = UART_ONE_BIT_SAMPLE_DISABLE;
  huart4.AdvancedInit.AdvFeatureInit = UART_ADVFEATURE_NO_INIT;
  if (HAL_UART_Init(&huart4) != HAL_OK)
  {
    Error_Handler();
  }

}

static void MX_USART3_UART_Init(void)
{

  huart3.Instance = USART3;
  huart3.Init.BaudRate = 115200;
  huart3.Init.WordLength = UART_WORDLENGTH_8B;
  huart3.Init.StopBits = UART_STOPBITS_1;
  huart3.Init.Parity = UART_PARITY_NONE;
  huart3.Init.Mode = UART_MODE_TX_RX;
  huart3.Init.HwFlowCtl = UART_HWCONTROL_NONE;
  huart3.Init.OverSampling = UART_OVERSAMPLING_16;
  huart3.Init.OneBitSampling = UART_ONE_BIT_SAMPLE_DISABLE;
  huart3.AdvancedInit.AdvFeatureInit = UART_ADVFEATURE_NO_INIT;
  if (HAL_UART_Init(&huart3) != HAL_OK)
  {
    Error_Handler();
  }

}

static void MX_DMA_Init(void)
{

  /* DMA controller clock enable */
  __HAL_RCC_DMA1_CLK_ENABLE();

  /* DMA interrupt init */
  /* DMA1_Stream2_IRQn interrupt configuration */
  HAL_NVIC_SetPriority(DMA1_Stream2_IRQn, 0, 0);
  HAL_NVIC_EnableIRQ(DMA1_Stream2_IRQn);
  /* DMA1_Stream5_IRQn interrupt configuration */
  HAL_NVIC_SetPriority(DMA1_Stream5_IRQn, 0, 0);
  HAL_NVIC_EnableIRQ(DMA1_Stream5_IRQn);
  /* DMA1_Stream6_IRQn interrupt configuration */
  HAL_NVIC_SetPriority(DMA1_Stream6_IRQn, 0, 0);
  HAL_NVIC_EnableIRQ(DMA1_Stream6_IRQn);

}

static void MX_GPIO_Init(void)
{
  GPIO_InitTypeDef GPIO_InitStruct = {0};

  /* GPIO Ports Clock Enable */
  __HAL_RCC_GPIOE_CLK_ENABLE();
  __HAL_RCC_GPIOC_CLK_ENABLE();
  __HAL_RCC_GPIOF_CLK_ENABLE();
  __HAL_RCC_GPIOH_CLK_ENABLE();
  __HAL_RCC_GPIOA_CLK_ENABLE();
  __HAL_RCC_GPIOB_CLK_ENABLE();
  __HAL_RCC_GPIOG_CLK_ENABLE();
  __HAL_RCC_GPIOD_CLK_ENABLE();

  /*Configure GPIO pin Output Level */
  HAL_GPIO_WritePin(GPIOE, GPIO_PIN_3|GPIO_PIN_4|GPIO_PIN_5|GPIO_PIN_6
                          |GPIO_PIN_14|GPIO_PIN_15, GPIO_PIN_RESET);

  /*Configure GPIO pin Output Level */
  HAL_GPIO_WritePin(GPIOF, GPIO_PIN_7|GPIO_PIN_8|GPIO_PIN_9, GPIO_PIN_RESET);

  /*Configure GPIO pin Output Level */
  HAL_GPIO_WritePin(GPIOB, LD1_Pin|GPIO_PIN_11|LD3_Pin|LD2_Pin, GPIO_PIN_RESET);

  /*Configure GPIO pin Output Level */
  HAL_GPIO_WritePin(GPIOG, GPIO_PIN_1|USB_PowerSwitchOn_Pin, GPIO_PIN_RESET);

  /*Configure GPIO pins : PE3 PE4 PE5 PE6
                           PE14 PE15 */
  GPIO_InitStruct.Pin = GPIO_PIN_3|GPIO_PIN_4|GPIO_PIN_5|GPIO_PIN_6
                          |GPIO_PIN_14|GPIO_PIN_15;
  GPIO_InitStruct.Mode = GPIO_MODE_OUTPUT_PP;
  GPIO_InitStruct.Pull = GPIO_NOPULL;
  GPIO_InitStruct.Speed = GPIO_SPEED_FREQ_LOW;
  HAL_GPIO_Init(GPIOE, &GPIO_InitStruct);

  /*Configure GPIO pins : PF7 PF8 PF9 */
  GPIO_InitStruct.Pin = GPIO_PIN_7|GPIO_PIN_8|GPIO_PIN_9;
  GPIO_InitStruct.Mode = GPIO_MODE_OUTPUT_PP;
  GPIO_InitStruct.Pull = GPIO_NOPULL;
  GPIO_InitStruct.Speed = GPIO_SPEED_FREQ_LOW;
  HAL_GPIO_Init(GPIOF, &GPIO_InitStruct);

  /*Configure GPIO pins : RMII_MDC_Pin RMII_RXD0_Pin RMII_RXD1_Pin */
  GPIO_InitStruct.Pin = RMII_MDC_Pin|RMII_RXD0_Pin|RMII_RXD1_Pin;
  GPIO_InitStruct.Mode = GPIO_MODE_AF_PP;
  GPIO_InitStruct.Pull = GPIO_NOPULL;
  GPIO_InitStruct.Speed = GPIO_SPEED_FREQ_VERY_HIGH;
  GPIO_InitStruct.Alternate = GPIO_AF11_ETH;
  HAL_GPIO_Init(GPIOC, &GPIO_InitStruct);

  /*Configure GPIO pins : RMII_REF_CLK_Pin RMII_MDIO_Pin RMII_CRS_DV_Pin */
  GPIO_InitStruct.Pin = RMII_REF_CLK_Pin|RMII_MDIO_Pin|RMII_CRS_DV_Pin;
  GPIO_InitStruct.Mode = GPIO_MODE_AF_PP;
  GPIO_InitStruct.Pull = GPIO_NOPULL;
  GPIO_InitStruct.Speed = GPIO_SPEED_FREQ_VERY_HIGH;
  GPIO_InitStruct.Alternate = GPIO_AF11_ETH;
  HAL_GPIO_Init(GPIOA, &GPIO_InitStruct);

  /*Configure GPIO pins : LD1_Pin PB11 LD3_Pin LD2_Pin */
  GPIO_InitStruct.Pin = LD1_Pin|GPIO_PIN_11|LD3_Pin|LD2_Pin;
  GPIO_InitStruct.Mode = GPIO_MODE_OUTPUT_PP;
  GPIO_InitStruct.Pull = GPIO_NOPULL;
  GPIO_InitStruct.Speed = GPIO_SPEED_FREQ_LOW;
  HAL_GPIO_Init(GPIOB, &GPIO_InitStruct);

  /*Configure GPIO pins : EXT_BTN_1_Pin EXT_BTN_4_Pin */
  GPIO_InitStruct.Pin = EXT_BTN_1_Pin|EXT_BTN_4_Pin;
  GPIO_InitStruct.Mode = GPIO_MODE_IT_FALLING;
  GPIO_InitStruct.Pull = GPIO_PULLUP;
  HAL_GPIO_Init(GPIOF, &GPIO_InitStruct);

  /*Configure GPIO pins : PG1 USB_PowerSwitchOn_Pin */
  GPIO_InitStruct.Pin = GPIO_PIN_1|USB_PowerSwitchOn_Pin;
  GPIO_InitStruct.Mode = GPIO_MODE_OUTPUT_PP;
  GPIO_InitStruct.Pull = GPIO_NOPULL;
  GPIO_InitStruct.Speed = GPIO_SPEED_FREQ_LOW;
  HAL_GPIO_Init(GPIOG, &GPIO_InitStruct);

  /*Configure GPIO pins : EXT_BTN_2_Pin EXT_BTN_3_Pin */
  GPIO_InitStruct.Pin = EXT_BTN_2_Pin|EXT_BTN_3_Pin;
  GPIO_InitStruct.Mode = GPIO_MODE_IT_FALLING;
  GPIO_InitStruct.Pull = GPIO_PULLUP;
  HAL_GPIO_Init(GPIOE, &GPIO_InitStruct);

  /*Configure GPIO pin : PE12 */
  GPIO_InitStruct.Pin = GPIO_PIN_12;
  GPIO_InitStruct.Mode = GPIO_MODE_INPUT;
  GPIO_InitStruct.Pull = GPIO_NOPULL;
  HAL_GPIO_Init(GPIOE, &GPIO_InitStruct);

  /*Configure GPIO pin : PB10 */
  GPIO_InitStruct.Pin = GPIO_PIN_10;
  GPIO_InitStruct.Mode = GPIO_MODE_ANALOG;
  GPIO_InitStruct.Pull = GPIO_NOPULL;
  HAL_GPIO_Init(GPIOB, &GPIO_InitStruct);

  /*Configure GPIO pin : RMII_TXD1_Pin */
  GPIO_InitStruct.Pin = RMII_TXD1_Pin;
  GPIO_InitStruct.Mode = GPIO_MODE_AF_PP;
  GPIO_InitStruct.Pull = GPIO_NOPULL;
  GPIO_InitStruct.Speed = GPIO_SPEED_FREQ_VERY_HIGH;
  GPIO_InitStruct.Alternate = GPIO_AF11_ETH;
  HAL_GPIO_Init(RMII_TXD1_GPIO_Port, &GPIO_InitStruct);

  /*Configure GPIO pin : USB_OverCurrent_Pin */
  GPIO_InitStruct.Pin = USB_OverCurrent_Pin;
  GPIO_InitStruct.Mode = GPIO_MODE_INPUT;
  GPIO_InitStruct.Pull = GPIO_NOPULL;
  HAL_GPIO_Init(USB_OverCurrent_GPIO_Port, &GPIO_InitStruct);

  /*Configure GPIO pins : USB_SOF_Pin USB_ID_Pin USB_DM_Pin USB_DP_Pin */
  GPIO_InitStruct.Pin = USB_SOF_Pin|USB_ID_Pin|USB_DM_Pin|USB_DP_Pin;
  GPIO_InitStruct.Mode = GPIO_MODE_AF_PP;
  GPIO_InitStruct.Pull = GPIO_NOPULL;
  GPIO_InitStruct.Speed = GPIO_SPEED_FREQ_VERY_HIGH;
  GPIO_InitStruct.Alternate = GPIO_AF10_OTG_FS;
  HAL_GPIO_Init(GPIOA, &GPIO_InitStruct);

  /*Configure GPIO pin : USB_VBUS_Pin */
  GPIO_InitStruct.Pin = USB_VBUS_Pin;
  GPIO_InitStruct.Mode = GPIO_MODE_INPUT;
  GPIO_InitStruct.Pull = GPIO_NOPULL;
  HAL_GPIO_Init(USB_VBUS_GPIO_Port, &GPIO_InitStruct);

  /*Configure GPIO pins : RMII_TX_EN_Pin RMII_TXD0_Pin */
  GPIO_InitStruct.Pin = RMII_TX_EN_Pin|RMII_TXD0_Pin;
  GPIO_InitStruct.Mode = GPIO_MODE_AF_PP;
  GPIO_InitStruct.Pull = GPIO_NOPULL;
  GPIO_InitStruct.Speed = GPIO_SPEED_FREQ_VERY_HIGH;
  GPIO_InitStruct.Alternate = GPIO_AF11_ETH;
  HAL_GPIO_Init(GPIOG, &GPIO_InitStruct);

  /* EXTI interrupt init*/
  HAL_NVIC_SetPriority(EXTI9_5_IRQn, 0, 0);
  HAL_NVIC_EnableIRQ(EXTI9_5_IRQn);

  HAL_NVIC_SetPriority(EXTI15_10_IRQn, 0, 0);
  HAL_NVIC_EnableIRQ(EXTI15_10_IRQn);

}

/* USER CODE BEGIN 4 */
// Callback para GPIOs
void HAL_GPIO_EXTI_Callback(uint16_t GPIO_Pin)
{
	if(GPIO_Pin == EXT_BTN_1_Pin) HAL_TIM_Base_Start_IT(&htim2);
	if(GPIO_Pin == EXT_BTN_2_Pin) HAL_TIM_Base_Start_IT(&htim2);
	if(GPIO_Pin == EXT_BTN_3_Pin) HAL_TIM_Base_Start_IT(&htim2);
	if(GPIO_Pin == EXT_BTN_4_Pin) HAL_TIM_Base_Start_IT(&htim2);
}
// Callback para Timers
void HAL_TIM_PeriodElapsedCallback(TIM_HandleTypeDef *htim)
{
  /* Prevent unused argument(s) compilation warning */
  if(htim == &htim2){
	  // Ya pasaron 40ms y sigue en 0, es real esto.
	  if(!HAL_GPIO_ReadPin(EXT_BTN_1_GPIO_Port, EXT_BTN_1_Pin)){
		  EXT_BTN_1_state = false;
		  HAL_TIM_Base_Stop(&htim2);
	  }
	  if(!HAL_GPIO_ReadPin(EXT_BTN_2_GPIO_Port, EXT_BTN_2_Pin)){
		  EXT_BTN_2_state = false;
		  HAL_TIM_Base_Stop(&htim2);
	  }
	  if(!HAL_GPIO_ReadPin(EXT_BTN_3_GPIO_Port, EXT_BTN_3_Pin)){
		  EXT_BTN_3_state = false;
		  HAL_TIM_Base_Stop(&htim2);
	  }
	  if(!HAL_GPIO_ReadPin(EXT_BTN_4_GPIO_Port, EXT_BTN_4_Pin)){
		  EXT_BTN_4_state = false;
		  HAL_TIM_Base_Stop(&htim2);
	  }
  }
}
void HAL_UART_RxCpltCallback(UART_HandleTypeDef *huart)
{
	for(i = 0; i < RX_BUFFER_SIZE; i++){
		if(rx_buffer[i] >= C2 && rx_buffer[i] <= B5){
//			repeated_note_flag = false;
//			// ¿Tocada antes?
//			for(j = 0; j < PLAYED_NOTES_BUFFER_SIZE; j++){
//				if(played_notes_buffer[j] == rx_buffer[i]){
//					repeated_note_flag = true;
//				}
//			}

			note_buffer[note_cnt] = rx_buffer[i];
			note_cnt++;
			received_note_buffer = rx_buffer[i];

			if(note_cnt >= NOTE_BUFFER_SIZE){
				note_cnt = 0;
			}

			HAL_DAC_Stop_DMA(&hdac, DAC_CHANNEL_1);
			HAL_DAC_Stop_DMA(&hdac, DAC_CHANNEL_2);
			htim6.Init.Prescaler = PSC_LUT[received_note_buffer - C2] - 1;
			htim6.Init.Period = ARR_LUT[received_note_buffer - C2] - 1;
			HAL_TIM_Base_Init(&htim6);
			  switch(selected_waveform){
				  case 1:
					  HAL_DAC_Start_DMA(&hdac, DAC_CHANNEL_1, sawtooth_to_sine_modulation, NS, DAC_ALIGN_12B_R);
					  HAL_DAC_Start_DMA(&hdac, DAC_CHANNEL_2, sawtooth_to_sine_modulation, NS, DAC_ALIGN_12B_R);
					  break;
				  case 2:
					  HAL_DAC_Start_DMA(&hdac, DAC_CHANNEL_1, sawtooth_to_square_modulation, NS, DAC_ALIGN_12B_R);
					  HAL_DAC_Start_DMA(&hdac, DAC_CHANNEL_2, sawtooth_to_square_modulation, NS, DAC_ALIGN_12B_R);
					  break;
				  case 3:
					  HAL_DAC_Start_DMA(&hdac, DAC_CHANNEL_1, sawtooth_to_triangle_modulation, NS, DAC_ALIGN_12B_R);
					  HAL_DAC_Start_DMA(&hdac, DAC_CHANNEL_2, sawtooth_to_triangle_modulation, NS, DAC_ALIGN_12B_R);
					  break;
				  case 5:
					  HAL_DAC_Start_DMA(&hdac, DAC_CHANNEL_1, triangle_to_sine_modulation, NS, DAC_ALIGN_12B_R);
					  HAL_DAC_Start_DMA(&hdac, DAC_CHANNEL_2, triangle_to_sine_modulation, NS, DAC_ALIGN_12B_R);
					  break;
				  case 6:
					  HAL_DAC_Start_DMA(&hdac, DAC_CHANNEL_1, triangle_to_square_modulation, NS, DAC_ALIGN_12B_R);
					  HAL_DAC_Start_DMA(&hdac, DAC_CHANNEL_2, triangle_to_square_modulation, NS, DAC_ALIGN_12B_R);
					  break;
				  case 7:
					  HAL_DAC_Start_DMA(&hdac, DAC_CHANNEL_1, triangle_to_triangle_modulation, NS, DAC_ALIGN_12B_R);
					  HAL_DAC_Start_DMA(&hdac, DAC_CHANNEL_2, triangle_to_triangle_modulation, NS, DAC_ALIGN_12B_R);
					  break;
				  case 8:
					  HAL_DAC_Start_DMA(&hdac, DAC_CHANNEL_1, triangle_to_sawtooth_modulation, NS, DAC_ALIGN_12B_R);
					  HAL_DAC_Start_DMA(&hdac, DAC_CHANNEL_2, triangle_to_sawtooth_modulation, NS, DAC_ALIGN_12B_R);
					  break;
				  case 9:
					  HAL_DAC_Start_DMA(&hdac, DAC_CHANNEL_1, square_to_sine_modulation, NS, DAC_ALIGN_12B_R);
					  HAL_DAC_Start_DMA(&hdac, DAC_CHANNEL_2, square_to_sine_modulation, NS, DAC_ALIGN_12B_R);
					  break;
				  case 10:
					  HAL_DAC_Start_DMA(&hdac, DAC_CHANNEL_1, square_to_square_modulation, NS, DAC_ALIGN_12B_R);
					  HAL_DAC_Start_DMA(&hdac, DAC_CHANNEL_2, square_to_square_modulation, NS, DAC_ALIGN_12B_R);
					  break;
				  case 11:
					  HAL_DAC_Start_DMA(&hdac, DAC_CHANNEL_1, square_to_triangle_modulation, NS, DAC_ALIGN_12B_R);
					  HAL_DAC_Start_DMA(&hdac, DAC_CHANNEL_2, square_to_triangle_modulation, NS, DAC_ALIGN_12B_R);
					  break;
				  case 12:
					  HAL_DAC_Start_DMA(&hdac, DAC_CHANNEL_1, square_to_sawtooth_modulation, NS, DAC_ALIGN_12B_R);
					  HAL_DAC_Start_DMA(&hdac, DAC_CHANNEL_2, square_to_sawtooth_modulation, NS, DAC_ALIGN_12B_R);
					  break;
				  case 14:
					  HAL_DAC_Start_DMA(&hdac, DAC_CHANNEL_1, square_LUT, NS, DAC_ALIGN_12B_R);
					  HAL_DAC_Start_DMA(&hdac, DAC_CHANNEL_2, square_LUT, NS, DAC_ALIGN_12B_R);
					  break;
				  case 15:
					  HAL_DAC_Start_DMA(&hdac, DAC_CHANNEL_1, triangle_LUT, NS, DAC_ALIGN_12B_R);
					  HAL_DAC_Start_DMA(&hdac, DAC_CHANNEL_2, triangle_LUT, NS, DAC_ALIGN_12B_R);
					  break;
				  case 16:
					  HAL_DAC_Start_DMA(&hdac, DAC_CHANNEL_1, sawtooth_LUT, NS, DAC_ALIGN_12B_R);
					  HAL_DAC_Start_DMA(&hdac, DAC_CHANNEL_2, sawtooth_LUT, NS, DAC_ALIGN_12B_R);
					  break;
				  default:
					  HAL_DAC_Start_DMA(&hdac, DAC_CHANNEL_1, sine_LUT, NS, DAC_ALIGN_12B_R);
					  HAL_DAC_Start_DMA(&hdac, DAC_CHANNEL_2, sine_LUT, NS, DAC_ALIGN_12B_R);
					  break;
			  }
		}
	}
}

/* USER CODE END 4 */

void Error_Handler(void)
{
}

/************************ (C) COPYRIGHT STMicroelectronics *****END OF FILE****/
